VERSION ""

NS_ :

BS_:

BU_:

BO_ 256 CANERR_OVER_CURRENT: 8 Vector__XXX
 SG_ data_3 : 63|8@0+ (1,0) [0|0] "" Vector__XXX
 SG_ data_2 : 55|8@0+ (1,0) [0|0] "" Vector__XXX
 SG_ data_1 : 47|8@0+ (1,0) [0|0] "" Vector__XXX
 SG_ data_0 : 39|8@0+ (1,0) [0|0] "" Vector__XXX
 SG_ node_id : 7|32@0+ (1,0) [0|0] "" Vector__XXX

BO_ 257 CANERR_OVER_VOLTAGE: 8 Vector__XXX
 SG_ data_3 : 63|8@0+ (1,0) [0|0] "" Vector__XXX
 SG_ data_2 : 55|8@0+ (1,0) [0|0] "" Vector__XXX
 SG_ data_1 : 47|8@0+ (1,0) [0|0] "" Vector__XXX
 SG_ data_0 : 39|8@0+ (1,0) [0|0] "" Vector__XXX
 SG_ node_id : 7|32@0+ (1,0) [0|0] "" Vector__XXX

BO_ 258 CANNERR_OVER_VOLTAGE: 8 Vector__XXX
 SG_ data_3 : 63|8@0+ (1,0) [0|0] "" Vector__XXX
 SG_ data_2 : 55|8@0+ (1,0) [0|0] "" Vector__XXX
 SG_ data_1 : 47|8@0+ (1,0) [0|0] "" Vector__XXX
 SG_ data_0 : 39|8@0+ (1,0) [0|0] "" Vector__XXX
 SG_ node_id : 7|32@0+ (1,0) [0|0] "" Vector__XXX

BO_ 259 CANERR_GEN_ALARM: 8 Vector__XXX
 SG_ data_3 : 63|8@0+ (1,0) [0|0] "" Vector__XXX
 SG_ data_2 : 55|8@0+ (1,0) [0|0] "" Vector__XXX
 SG_ data_1 : 47|8@0+ (1,0) [0|0] "" Vector__XXX
 SG_ data_0 : 39|8@0+ (1,0) [0|0] "" Vector__XXX
 SG_ node_id : 7|32@0+ (1,0) [0|0] "" Vector__XXX

BO_ 260 CANERR_STORED_ERROR: 8 Vector__XXX
 SG_ data_3 : 63|8@0+ (1,0) [0|0] "" Vector__XXX
 SG_ data_2 : 55|8@0+ (1,0) [0|0] "" Vector__XXX
 SG_ data_1 : 47|8@0+ (1,0) [0|0] "" Vector__XXX
 SG_ data_0 : 39|8@0+ (1,0) [0|0] "" Vector__XXX
 SG_ node_id : 7|32@0+ (1,0) [0|0] "" Vector__XXX

BO_ 261 CANERR_RESERVED_105: 4 Vector__XXX
 SG_ node_id : 7|32@0+ (1,0) [0|0] "" Vector__XXX

BO_ 262 CANERR_RESERVED_106: 4 Vector__XXX
 SG_ node_id : 7|32@0+ (1,0) [0|0] "" Vector__XXX

BO_ 263 CANERR_RESERVED_107: 4 Vector__XXX
 SG_ node_id : 7|32@0+ (1,0) [0|0] "" Vector__XXX

BO_ 264 CANERR_RESERVED_108: 4 Vector__XXX
 SG_ node_id : 7|32@0+ (1,0) [0|0] "" Vector__XXX

BO_ 265 CANERR_RESERVED_109: 4 Vector__XXX
 SG_ node_id : 7|32@0+ (1,0) [0|0] "" Vector__XXX

BO_ 272 SW_RESERVED_110: 4 Vector__XXX
 SG_ node_id : 7|32@0+ (1,0) [0|0] "" Vector__XXX

BO_ 273 SW_RESERVED_111: 4 Vector__XXX
 SG_ node_id : 7|32@0+ (1,0) [0|0] "" Vector__XXX

BO_ 274 SW_SET_MODE: 6 Vector__XXX
 SG_ switch_mode : 47|8@0+ (1,0) [0|0] "" Vector__XXX
 SG_ switch_id : 39|8@0+ (1,0) [0|0] "" Vector__XXX
 SG_ node_id : 7|32@0+ (1,0) [0|0] "" Vector__XXX

BO_ 275 SW_SET_OFF: 5 Vector__XXX
 SG_ switch_id : 39|8@0+ (1,0) [0|0] "" Vector__XXX
 SG_ node_id : 7|32@0+ (1,0) [0|0] "" Vector__XXX

BO_ 276 SW_SET_ON: 5 Vector__XXX
 SG_ switch_id : 39|8@0+ (1,0) [0|0] "" Vector__XXX
 SG_ node_id : 7|32@0+ (1,0) [0|0] "" Vector__XXX

BO_ 277 SW_MOM_PRESS: 5 Vector__XXX
 SG_ switch_id : 39|8@0+ (1,0) [0|0] "" Vector__XXX
 SG_ node_id : 7|32@0+ (1,0) [0|0] "" Vector__XXX

BO_ 278 SW_SET_MOM_DUR: 6 Vector__XXX
 SG_ duration : 47|8@0+ (1,0) [0|0] "" Vector__XXX
 SG_ switch_id : 39|8@0+ (1,0) [0|0] "" Vector__XXX
 SG_ node_id : 7|32@0+ (1,0) [0|0] "" Vector__XXX

BO_ 279 SW_SET_PWM_DUTY: 6 Vector__XXX
 SG_ duty : 47|8@0+ (1,0) [0|0] "" Vector__XXX
 SG_ switch_id : 39|8@0+ (1,0) [0|0] "" Vector__XXX
 SG_ node_id : 7|32@0+ (1,0) [0|0] "" Vector__XXX

BO_ 280 SW_SET_PWM_FREQ: 6 Vector__XXX
 SG_ freq : 47|8@0+ (1,0) [0|0] "" Vector__XXX
 SG_ switch_id : 39|8@0+ (1,0) [0|0] "" Vector__XXX
 SG_ node_id : 7|32@0+ (1,0) [0|0] "" Vector__XXX

BO_ 281 SW_SET_BLINK_DELAY: 6 Vector__XXX
 SG_ blink_rate : 47|8@0+ (1,0) [0|0] "" Vector__XXX
 SG_ switch_id : 39|8@0+ (1,0) [0|0] "" Vector__XXX
 SG_ node_id : 7|32@0+ (1,0) [0|0] "" Vector__XXX

BO_ 282 SW_SET_STROBE_PAT: 6 Vector__XXX
 SG_ strobe_pattern : 47|8@0+ (1,0) [0|0] "" Vector__XXX
 SG_ switch_id : 39|8@0+ (1,0) [0|0] "" Vector__XXX
 SG_ node_id : 7|32@0+ (1,0) [0|0] "" Vector__XXX

BO_ 283 SW_SET_STATE_MEM: 6 Vector__XXX
 SG_ memory : 47|8@0+ (1,0) [0|0] "" Vector__XXX
 SG_ switch_id : 39|8@0+ (1,0) [0|0] "" Vector__XXX
 SG_ node_id : 7|32@0+ (1,0) [0|0] "" Vector__XXX

BO_ 284 SW_RESERVED_11C: 4 Vector__XXX
 SG_ node_id : 7|32@0+ (1,0) [0|0] "" Vector__XXX

BO_ 285 SW_RESERVED_11D: 4 Vector__XXX
 SG_ node_id : 7|32@0+ (1,0) [0|0] "" Vector__XXX

BO_ 286 SW_RESERVED_11E: 4 Vector__XXX
 SG_ node_id : 7|32@0+ (1,0) [0|0] "" Vector__XXX

BO_ 287 SW_RESERVED_11F: 4 Vector__XXX
 SG_ node_id : 7|32@0+ (1,0) [0|0] "" Vector__XXX

BO_ 314 SW_RESERVED_13A: 4 Vector__XXX
 SG_ node_id : 7|32@0+ (1,0) [0|0] "" Vector__XXX

BO_ 315 SW_RESERVED_13B: 4 Vector__XXX
 SG_ node_id : 7|32@0+ (1,0) [0|0] "" Vector__XXX

BO_ 316 SW_RESERVED_13C: 4 Vector__XXX
 SG_ node_id : 7|32@0+ (1,0) [0|0] "" Vector__XXX

BO_ 317 SW_RESERVED_13D: 4 Vector__XXX
 SG_ node_id : 7|32@0+ (1,0) [0|0] "" Vector__XXX

BO_ 318 SW_RESERVED_13E: 4 Vector__XXX
 SG_ node_id : 7|32@0+ (1,0) [0|0] "" Vector__XXX

BO_ 319 SW_RESERVED_13F: 4 Vector__XXX
 SG_ node_id : 7|32@0+ (1,0) [0|0] "" Vector__XXX

BO_ 512 SET_DISPLAY_OFF: 5 Vector__XXX
 SG_ display_id : 39|8@0+ (1,0) [0|0] "" Vector__XXX
 SG_ node_id : 7|32@0+ (1,0) [0|0] "" Vector__XXX

BO_ 513 SET_DISPLAY_ON: 5 Vector__XXX
 SG_ display_id : 39|8@0+ (1,0) [0|0] "" Vector__XXX
 SG_ node_id : 7|32@0+ (1,0) [0|0] "" Vector__XXX

BO_ 514 SET_DISPLAY_CLEAR: 5 Vector__XXX
 SG_ display_id : 39|8@0+ (1,0) [0|0] "" Vector__XXX
 SG_ node_id : 7|32@0+ (1,0) [0|0] "" Vector__XXX

BO_ 515 SET_DISPLAY_FLASH: 6 Vector__XXX
 SG_ flash_rate : 47|8@0+ (1,0) [0|0] "" Vector__XXX
 SG_ display_id : 39|8@0+ (1,0) [0|0] "" Vector__XXX
 SG_ node_id : 7|32@0+ (1,0) [0|0] "" Vector__XXX

BO_ 516 SET_DISPLAY_BACKLIGHT_COLOR: 6 Vector__XXX
 SG_ color_index : 47|8@0+ (1,0) [0|0] "" Vector__XXX
 SG_ display_id : 39|8@0+ (1,0) [0|0] "" Vector__XXX
 SG_ node_id : 7|32@0+ (1,0) [0|0] "" Vector__XXX

BO_ 517 SET_DISPLAY_BACKLIGHT_BRIGHTNESS: 6 Vector__XXX
 SG_ brightness : 47|8@0+ (1,0) [0|0] "" Vector__XXX
 SG_ display_id : 39|8@0+ (1,0) [0|0] "" Vector__XXX
 SG_ node_id : 7|32@0+ (1,0) [0|0] "" Vector__XXX

BO_ 518 REQ_DISPLAY_CONFIG: 7 Vector__XXX
 SG_ msg_id : 47|16@0+ (1,0) [0|0] "" Vector__XXX
 SG_ display_id : 39|8@0+ (1,0) [0|0] "" Vector__XXX
 SG_ node_id : 7|32@0+ (1,0) [0|0] "" Vector__XXX

BO_ 519 REQ_DISPLAY_DATA: 7 Vector__XXX
 SG_ msg_id : 47|16@0+ (1,0) [0|0] "" Vector__XXX
 SG_ display_id : 39|8@0+ (1,0) [0|0] "" Vector__XXX
 SG_ node_id : 7|32@0+ (1,0) [0|0] "" Vector__XXX

BO_ 520 SET_OLED_FIELD_COLOR: 6 Vector__XXX
 SG_ color_index : 47|8@0+ (1,0) [0|0] "" Vector__XXX
 SG_ display_id : 39|8@0+ (1,0) [0|0] "" Vector__XXX
 SG_ node_id : 7|32@0+ (1,0) [0|0] "" Vector__XXX

BO_ 521 SET_OLED_FIELD_BLINK: 7 Vector__XXX
 SG_ blink_rate : 47|16@0+ (1,0) [0|0] "" Vector__XXX
 SG_ display_id : 39|8@0+ (1,0) [0|0] "" Vector__XXX
 SG_ node_id : 7|32@0+ (1,0) [0|0] "" Vector__XXX

BO_ 522 SET_OLED_FIELD_STROBE: 6 Vector__XXX
 SG_ strobe_pattern : 47|8@0+ (1,0) [0|0] "" Vector__XXX
 SG_ display_id : 39|8@0+ (1,0) [0|0] "" Vector__XXX
 SG_ node_id : 7|32@0+ (1,0) [0|0] "" Vector__XXX

BO_ 523 SET_DISPLAY_RESERVED_20B: 4 Vector__XXX
 SG_ node_id : 7|32@0+ (1,0) [0|0] "" Vector__XXX

BO_ 524 SET_DISPLAY_RESERVED_20C: 4 Vector__XXX
 SG_ node_id : 7|32@0+ (1,0) [0|0] "" Vector__XXX

BO_ 525 DISPLAY_DATA_MSG: 8 Vector__XXX
 SG_ display_data : 7|64@0+ (1,0) [0|0] "" Vector__XXX

BO_ 526 DISPLAY_DATA_ACK: 8 Vector__XXX
 SG_ display_data : 7|64@0+ (1,0) [0|0] "" Vector__XXX

BO_ 527 SET_DISPLAY_RESERVED_20F: 4 Vector__XXX
 SG_ node_id : 7|32@0+ (1,0) [0|0] "" Vector__XXX

BO_ 528 SET_ARGB_STRIP_COLOR: 6 Vector__XXX
 SG_ color_index : 47|8@0+ (1,0) [0|0] "" Vector__XXX
 SG_ display_id : 39|8@0+ (1,0) [0|0] "" Vector__XXX
 SG_ node_id : 7|32@0+ (1,0) [0|0] "" Vector__XXX

BO_ 529 SET_ARGBW_STRIP_COLOR: 6 Vector__XXX
 SG_ color_index : 47|8@0+ (1,0) [0|0] "" Vector__XXX
 SG_ display_id : 39|8@0+ (1,0) [0|0] "" Vector__XXX
 SG_ node_id : 7|32@0+ (1,0) [0|0] "" Vector__XXX

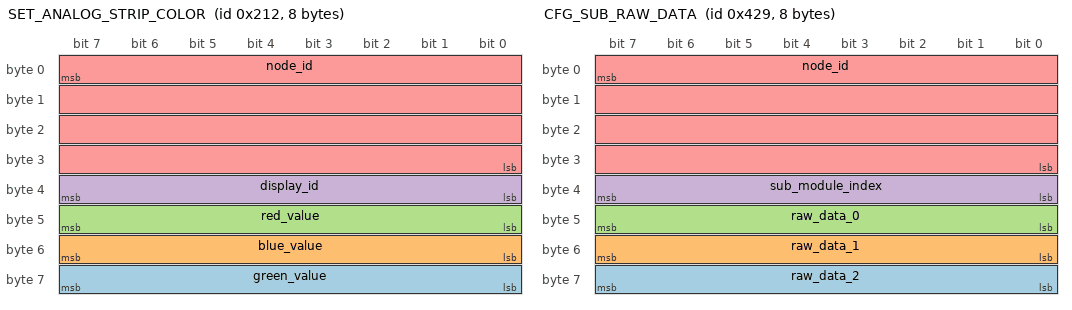
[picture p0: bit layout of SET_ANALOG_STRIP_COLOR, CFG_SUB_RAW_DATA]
BO_ 530 SET_ANALOG_STRIP_COLOR: 8 Vector__XXX
 SG_ green_value : 63|8@0+ (1,0) [0|0] "" Vector__XXX
 SG_ blue_value : 55|8@0+ (1,0) [0|0] "" Vector__XXX
 SG_ red_value : 47|8@0+ (1,0) [0|0] "" Vector__XXX
 SG_ display_id : 39|8@0+ (1,0) [0|0] "" Vector__XXX
 SG_ node_id : 7|32@0+ (1,0) [0|0] "" Vector__XXX

BO_ 531 SET_ADDR_STRIP_EFFECT: 6 Vector__XXX
 SG_ effect_index : 47|8@0+ (1,0) [0|0] "" Vector__XXX
 SG_ display_id : 39|8@0+ (1,0) [0|0] "" Vector__XXX
 SG_ node_id : 7|32@0+ (1,0) [0|0] "" Vector__XXX

BO_ 532 SET_LED_STRIP_BRIGHTNESS: 6 Vector__XXX
 SG_ brightness : 47|8@0+ (1,0) [0|0] "" Vector__XXX
 SG_ display_id : 39|8@0+ (1,0) [0|0] "" Vector__XXX
 SG_ node_id : 7|32@0+ (1,0) [0|0] "" Vector__XXX

BO_ 533 SET_LED_STRIP_OFF: 5 Vector__XXX
 SG_ display_id : 39|8@0+ (1,0) [0|0] "" Vector__XXX
 SG_ node_id : 7|32@0+ (1,0) [0|0] "" Vector__XXX

BO_ 534 SET_LED_STRIP_ON: 5 Vector__XXX
 SG_ display_id : 39|8@0+ (1,0) [0|0] "" Vector__XXX
 SG_ node_id : 7|32@0+ (1,0) [0|0] "" Vector__XXX

BO_ 535 SET_LED_RESERVED_217: 4 Vector__XXX
 SG_ node_id : 7|32@0+ (1,0) [0|0] "" Vector__XXX

BO_ 536 SET_LED_RESERVED_218: 4 Vector__XXX
 SG_ node_id : 7|32@0+ (1,0) [0|0] "" Vector__XXX

BO_ 537 SET_LED_RESERVED_219: 4 Vector__XXX
 SG_ node_id : 7|32@0+ (1,0) [0|0] "" Vector__XXX

BO_ 538 SET_LED_RESERVED_21A: 4 Vector__XXX
 SG_ node_id : 7|32@0+ (1,0) [0|0] "" Vector__XXX

BO_ 539 SET_LED_RESERVED_21B: 4 Vector__XXX
 SG_ node_id : 7|32@0+ (1,0) [0|0] "" Vector__XXX

BO_ 540 SET_LED_RESERVED_21C: 4 Vector__XXX
 SG_ node_id : 7|32@0+ (1,0) [0|0] "" Vector__XXX

BO_ 541 SET_LED_RESERVED_21D: 4 Vector__XXX
 SG_ node_id : 7|32@0+ (1,0) [0|0] "" Vector__XXX

BO_ 542 SET_LED_RESERVED_21E: 4 Vector__XXX
 SG_ node_id : 7|32@0+ (1,0) [0|0] "" Vector__XXX

BO_ 543 SET_LED_RESERVED_21F: 4 Vector__XXX
 SG_ node_id : 7|32@0+ (1,0) [0|0] "" Vector__XXX

BO_ 544 SET_ARGB_BUTTON_COLOR: 6 Vector__XXX
 SG_ color_index : 47|8@0+ (1,0) [0|0] "" Vector__XXX
 SG_ button_id : 39|8@0+ (1,0) [0|0] "" Vector__XXX
 SG_ node_id : 7|32@0+ (1,0) [0|0] "" Vector__XXX

BO_ 545 SET_ARGB_BUTTON_LED_MODE: 6 Vector__XXX
 SG_ mode_select : 47|8@0+ (1,0) [0|0] "" Vector__XXX
 SG_ button_id : 39|8@0+ (1,0) [0|0] "" Vector__XXX
 SG_ node_id : 7|32@0+ (1,0) [0|0] "" Vector__XXX

BO_ 546 SET_BUTTON_MODE: 4 Vector__XXX
 SG_ node_id : 7|32@0+ (1,0) [0|0] "" Vector__XXX

BO_ 547 SET_BUTTON_RESERVED_223: 4 Vector__XXX
 SG_ node_id : 7|32@0+ (1,0) [0|0] "" Vector__XXX

BO_ 548 SET_BUTTON_RESERVED_224: 4 Vector__XXX
 SG_ node_id : 7|32@0+ (1,0) [0|0] "" Vector__XXX

BO_ 549 SET_BUTTON_RESERVED_225: 4 Vector__XXX
 SG_ node_id : 7|32@0+ (1,0) [0|0] "" Vector__XXX

BO_ 550 SET_BUTTON_RESERVED_226: 4 Vector__XXX
 SG_ node_id : 7|32@0+ (1,0) [0|0] "" Vector__XXX

BO_ 551 SET_BUTTON_RESERVED_227: 4 Vector__XXX
 SG_ node_id : 7|32@0+ (1,0) [0|0] "" Vector__XXX

BO_ 552 SET_BUTTON_RESERVED_228: 4 Vector__XXX
 SG_ node_id : 7|32@0+ (1,0) [0|0] "" Vector__XXX

BO_ 553 SET_BUTTON_RESERVED_229: 4 Vector__XXX
 SG_ node_id : 7|32@0+ (1,0) [0|0] "" Vector__XXX

BO_ 554 SET_BUTTON_RESERVED_22A: 4 Vector__XXX
 SG_ node_id : 7|32@0+ (1,0) [0|0] "" Vector__XXX

BO_ 555 SET_BUTTON_RESERVED_22B: 4 Vector__XXX
 SG_ node_id : 7|32@0+ (1,0) [0|0] "" Vector__XXX

BO_ 556 SET_BUTTON_RESERVED_22C: 4 Vector__XXX
 SG_ node_id : 7|32@0+ (1,0) [0|0] "" Vector__XXX

BO_ 557 SET_BUTTON_RESERVED_22D: 4 Vector__XXX
 SG_ node_id : 7|32@0+ (1,0) [0|0] "" Vector__XXX

BO_ 558 SET_BUTTON_RESERVED_22E: 4 Vector__XXX
 SG_ node_id : 7|32@0+ (1,0) [0|0] "" Vector__XXX

BO_ 559 SET_BUTTON_RESERVED_22F: 4 Vector__XXX
 SG_ node_id : 7|32@0+ (1,0) [0|0] "" Vector__XXX

BO_ 1024 ACK_INTRO: 4 Vector__XXX
 SG_ node_id : 7|32@0+ (1,0) [0|0] "" Vector__XXX

BO_ 1025 REQ_NODE_INTRO: 4 Vector__XXX
 SG_ node_id : 7|32@0+ (1,0) [0|0] "" Vector__XXX

BO_ 1026 MSG_NORM_OPER: 4 Vector__XXX
 SG_ node_id : 7|32@0+ (1,0) [0|0] "" Vector__XXX

BO_ 1027 MSG_HALT_OPER: 4 Vector__XXX
 SG_ node_id : 7|32@0+ (1,0) [0|0] "" Vector__XXX

BO_ 1028 REQ_NODECHECK: 4 Vector__XXX
 SG_ node_id : 7|32@0+ (1,0) [0|0] "" Vector__XXX

BO_ 1029 REQ_HEALTHCHECK: 4 Vector__XXX
 SG_ node_id : 7|32@0+ (1,0) [0|0] "" Vector__XXX

BO_ 1030 REQ_IFACE: 4 Vector__XXX
 SG_ node_id : 7|32@0+ (1,0) [0|0] "" Vector__XXX

BO_ 1031 REQ_SWITCHBOX: 4 Vector__XXX
 SG_ node_id : 7|32@0+ (1,0) [0|0] "" Vector__XXX

BO_ 1032 REQ_RESERVED_408: 4 Vector__XXX
 SG_ node_id : 7|32@0+ (1,0) [0|0] "" Vector__XXX

BO_ 1033 REQ_RESERVED_409: 4 Vector__XXX
 SG_ node_id : 7|32@0+ (1,0) [0|0] "" Vector__XXX

BO_ 1034 REQ_RESERVED_40A: 4 Vector__XXX
 SG_ node_id : 7|32@0+ (1,0) [0|0] "" Vector__XXX

BO_ 1035 REQ_RESERVED_40B: 4 Vector__XXX
 SG_ node_id : 7|32@0+ (1,0) [0|0] "" Vector__XXX

BO_ 1036 DATA_EPOCH: 8 Vector__XXX
 SG_ unixtime : 39|32@0+ (1,0) [0|0] "" Vector__XXX
 SG_ node_id : 7|32@0+ (1,0) [0|0] "" Vector__XXX

BO_ 1037 DATA_SENSOR_MSG: 6 Vector__XXX
 SG_ data_msg_id : 39|16@0+ (1,0) [0|0] "" Vector__XXX
 SG_ node_id : 7|32@0+ (1,0) [0|0] "" Vector__XXX

BO_ 1038 REQ_RESERVED_40E: 4 Vector__XXX
 SG_ node_id : 7|32@0+ (1,0) [0|0] "" Vector__XXX

BO_ 1039 REQ_RESERVED_40F: 4 Vector__XXX
 SG_ node_id : 7|32@0+ (1,0) [0|0] "" Vector__XXX

BO_ 1040 REQ_DIGITAL_INPUTS: 4 Vector__XXX
 SG_ node_id : 7|32@0+ (1,0) [0|0] "" Vector__XXX

BO_ 1041 REQ_DIGITAL_OUTPUTS: 4 Vector__XXX
 SG_ node_id : 7|32@0+ (1,0) [0|0] "" Vector__XXX

BO_ 1042 REQ_DISPLAYS: 4 Vector__XXX
 SG_ node_id : 7|32@0+ (1,0) [0|0] "" Vector__XXX

BO_ 1043 REQ_TEMP_SENSOR: 4 Vector__XXX
 SG_ node_id : 7|32@0+ (1,0) [0|0] "" Vector__XXX

BO_ 1044 REQ_VOLT_SENSOR: 4 Vector__XXX
 SG_ node_id : 7|32@0+ (1,0) [0|0] "" Vector__XXX

BO_ 1045 REQ_AMP_SENSOR: 4 Vector__XXX
 SG_ node_id : 7|32@0+ (1,0) [0|0] "" Vector__XXX

BO_ 1046 REQ_ANALOG_INPUTS: 4 Vector__XXX
 SG_ node_id : 7|32@0+ (1,0) [0|0] "" Vector__XXX

BO_ 1047 REQ_AMBIENT_LIGHT: 4 Vector__XXX
 SG_ node_id : 7|32@0+ (1,0) [0|0] "" Vector__XXX

BO_ 1048 REQ_IMU_SENSORS: 4 Vector__XXX
 SG_ node_id : 7|32@0+ (1,0) [0|0] "" Vector__XXX

BO_ 1049 REQ_RESERVED_419: 4 Vector__XXX
 SG_ node_id : 7|32@0+ (1,0) [0|0] "" Vector__XXX

BO_ 1050 REQ_RESERVED_41A: 4 Vector__XXX
 SG_ node_id : 7|32@0+ (1,0) [0|0] "" Vector__XXX

BO_ 1051 REQ_RESERVED_41B: 4 Vector__XXX
 SG_ node_id : 7|32@0+ (1,0) [0|0] "" Vector__XXX

BO_ 1052 REQ_RESERVED_41C: 4 Vector__XXX
 SG_ node_id : 7|32@0+ (1,0) [0|0] "" Vector__XXX

BO_ 1053 REQ_RESERVED_41D: 4 Vector__XXX
 SG_ node_id : 7|32@0+ (1,0) [0|0] "" Vector__XXX

BO_ 1054 REQ_RESERVED_41E: 4 Vector__XXX
 SG_ node_id : 7|32@0+ (1,0) [0|0] "" Vector__XXX

BO_ 1055 REQ_RESERVED_41F: 4 Vector__XXX
 SG_ node_id : 7|32@0+ (1,0) [0|0] "" Vector__XXX

BO_ 1056 CFG_RESERVED_420: 4 Vector__XXX
 SG_ node_id : 7|32@0+ (1,0) [0|0] "" Vector__XXX

BO_ 1057 CFG_RESERVED_421: 4 Vector__XXX
 SG_ node_id : 7|32@0+ (1,0) [0|0] "" Vector__XXX

BO_ 1058 CFG_RESERVED_422: 4 Vector__XXX
 SG_ node_id : 7|32@0+ (1,0) [0|0] "" Vector__XXX

BO_ 1059 CFG_RESERVED_423: 4 Vector__XXX
 SG_ node_id : 7|32@0+ (1,0) [0|0] "" Vector__XXX

BO_ 1060 CFG_RESERVED_424: 4 Vector__XXX
 SG_ node_id : 7|32@0+ (1,0) [0|0] "" Vector__XXX

BO_ 1061 CFG_RESERVED_425: 4 Vector__XXX
 SG_ node_id : 7|32@0+ (1,0) [0|0] "" Vector__XXX

BO_ 1062 CFG_RESERVED_426: 4 Vector__XXX
 SG_ node_id : 7|32@0+ (1,0) [0|0] "" Vector__XXX

BO_ 1063 CFG_RESERVED_427: 4 Vector__XXX
 SG_ node_id : 7|32@0+ (1,0) [0|0] "" Vector__XXX

BO_ 1064 CFG_RESERVED_428: 4 Vector__XXX
 SG_ node_id : 7|32@0+ (1,0) [0|0] "" Vector__XXX

BO_ 1065 CFG_SUB_RAW_DATA: 8 Vector__XXX
 SG_ raw_data_2 : 63|8@0+ (1,0) [0|0] "" Vector__XXX
 SG_ raw_data_1 : 55|8@0+ (1,0) [0|0] "" Vector__XXX
 SG_ raw_data_0 : 47|8@0+ (1,0) [0|0] "" Vector__XXX
 SG_ sub_module_index : 39|8@0+ (1,0) [0|0] "" Vector__XXX
 SG_ node_id : 7|32@0+ (1,0) [0|0] "" Vector__XXX

BO_ 1066 CFG_NODE_DATA_MSG: 7 Vector__XXX
 SG_ datamsg_dlc : 55|8@0+ (1,0) [0|0] "" Vector__XXX
 SG_ datamsg_id : 39|16@0+ (1,0) [0|0] "" Vector__XXX
 SG_ node_id : 7|32@0+ (1,0) [0|0] "" Vector__XXX

BO_ 1067 CFG_NODE_INTRO_MSG: 7 Vector__XXX
 SG_ intromsg_dlc : 55|8@0+ (1,0) [0|0] "" Vector__XXX
 SG_ intromsg_id : 39|16@0+ (1,0) [0|0] "" Vector__XXX
 SG_ node_id : 7|32@0+ (1,0) [0|0] "" Vector__XXX

BO_ 1068 CFG_SUB_DATA_MSG: 8 Vector__XXX
 SG_ datamsg_dlc : 63|8@0+ (1,0) [0|0] "" Vector__XXX
 SG_ datamsg_id : 47|16@0+ (1,0) [0|0] "" Vector__XXX
 SG_ sub_module_index : 39|8@0+ (1,0) [0|0] "" Vector__XXX
 SG_ node_id : 7|32@0+ (1,0) [0|0] "" Vector__XXX

BO_ 1069 CFG_SUB_INTRO_MSG: 8 Vector__XXX
 SG_ intromsg_dlc : 63|8@0+ (1,0) [0|0] "" Vector__XXX
 SG_ intromsg_id : 47|16@0+ (1,0) [0|0] "" Vector__XXX
 SG_ sub_module_index : 39|8@0+ (1,0) [0|0] "" Vector__XXX
 SG_ node_id : 7|32@0+ (1,0) [0|0] "" Vector__XXX

BO_ 1070 COLORPICKER_READ_NVS: 4 Vector__XXX
 SG_ node_id : 7|32@0+ (1,0) [0|0] "" Vector__XXX

BO_ 1071 COLORPICKER_WRITE_NVS: 4 Vector__XXX
 SG_ node_id : 7|32@0+ (1,0) [0|0] "" Vector__XXX

BO_ 1072 COLORPICKER_SEND_LIST: 4 Vector__XXX
 SG_ node_id : 7|32@0+ (1,0) [0|0] "" Vector__XXX

BO_ 1073 COLORPICKER_PURGE_LIST: 4 Vector__XXX
 SG_ node_id : 7|32@0+ (1,0) [0|0] "" Vector__XXX

BO_ 1074 COLORPICKER_DEL_NODE: 8 Vector__XXX
 SG_ remote_id : 39|32@0+ (1,0) [0|0] "" Vector__XXX
 SG_ node_id : 7|32@0+ (1,0) [0|0] "" Vector__XXX

BO_ 1075 COLORPICKER_ADD_NODE: 8 Vector__XXX
 SG_ remote_id : 39|32@0+ (1,0) [0|0] "" Vector__XXX
 SG_ node_id : 7|32@0+ (1,0) [0|0] "" Vector__XXX

BO_ 1076 CFG_ERASE_NVS: 4 Vector__XXX
 SG_ node_id : 7|32@0+ (1,0) [0|0] "" Vector__XXX

BO_ 1077 CFG_REBOOT: 4 Vector__XXX
 SG_ node_id : 7|32@0+ (1,0) [0|0] "" Vector__XXX

BO_ 1078 CFG_WRITE_NVS: 6 Vector__XXX
 SG_ crc_16 : 39|16@0+ (1,0) [0|0] "" Vector__XXX
 SG_ node_id : 7|32@0+ (1,0) [0|0] "" Vector__XXX

BO_ 1079 CFG_READ_NVS: 6 Vector__XXX
 SG_ crc_16 : 39|16@0+ (1,0) [0|0] "" Vector__XXX
 SG_ node_id : 7|32@0+ (1,0) [0|0] "" Vector__XXX

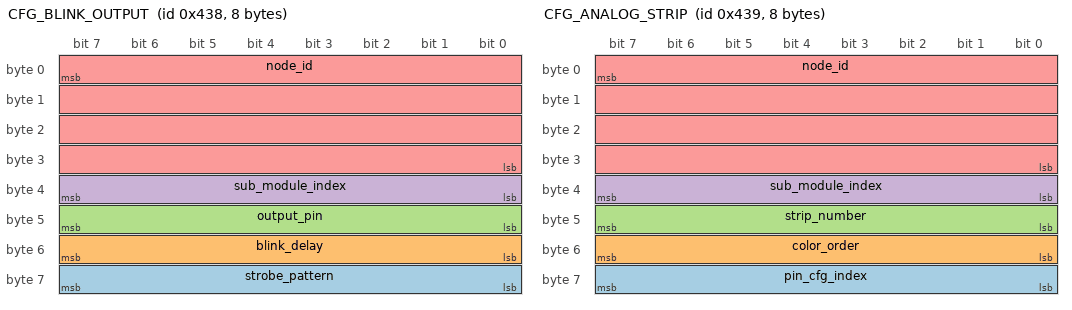
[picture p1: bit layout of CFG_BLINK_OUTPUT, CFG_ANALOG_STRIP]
BO_ 1080 CFG_BLINK_OUTPUT: 8 Vector__XXX
 SG_ strobe_pattern : 63|8@0+ (1,0) [0|0] "" Vector__XXX
 SG_ blink_delay : 55|8@0+ (1,0) [0|0] "" Vector__XXX
 SG_ output_pin : 47|8@0+ (1,0) [0|0] "" Vector__XXX
 SG_ sub_module_index : 39|8@0+ (1,0) [0|0] "" Vector__XXX
 SG_ node_id : 7|32@0+ (1,0) [0|0] "" Vector__XXX

BO_ 1081 CFG_ANALOG_STRIP: 8 Vector__XXX
 SG_ pin_cfg_index : 63|8@0+ (1,0) [0|0] "" Vector__XXX
 SG_ color_order : 55|8@0+ (1,0) [0|0] "" Vector__XXX
 SG_ strip_number : 47|8@0+ (1,0) [0|0] "" Vector__XXX
 SG_ sub_module_index : 39|8@0+ (1,0) [0|0] "" Vector__XXX
 SG_ node_id : 7|32@0+ (1,0) [0|0] "" Vector__XXX

BO_ 1082 CFG_ARGB_STRIP: 8 Vector__XXX
 SG_ led_count : 55|16@0+ (1,0) [0|0] "" Vector__XXX
 SG_ output_pin : 47|8@0+ (1,0) [0|0] "" Vector__XXX
 SG_ sub_module_index : 39|8@0+ (1,0) [0|0] "" Vector__XXX
 SG_ node_id : 7|32@0+ (1,0) [0|0] "" Vector__XXX

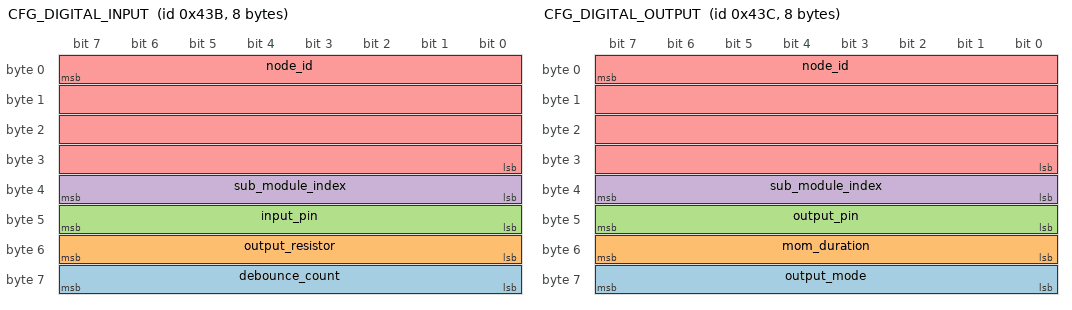
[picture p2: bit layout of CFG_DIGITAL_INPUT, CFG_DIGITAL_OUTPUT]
BO_ 1083 CFG_DIGITAL_INPUT: 8 Vector__XXX
 SG_ debounce_count : 63|8@0+ (1,0) [0|0] "" Vector__XXX
 SG_ output_resistor : 55|8@0+ (1,0) [0|0] "" Vector__XXX
 SG_ input_pin : 47|8@0+ (1,0) [0|0] "" Vector__XXX
 SG_ sub_module_index : 39|8@0+ (1,0) [0|0] "" Vector__XXX
 SG_ node_id : 7|32@0+ (1,0) [0|0] "" Vector__XXX

BO_ 1084 CFG_DIGITAL_OUTPUT: 8 Vector__XXX
 SG_ output_mode : 63|8@0+ (1,0) [0|0] "" Vector__XXX
 SG_ mom_duration : 55|8@0+ (1,0) [0|0] "" Vector__XXX
 SG_ output_pin : 47|8@0+ (1,0) [0|0] "" Vector__XXX
 SG_ sub_module_index : 39|8@0+ (1,0) [0|0] "" Vector__XXX
 SG_ node_id : 7|32@0+ (1,0) [0|0] "" Vector__XXX

BO_ 1085 CFG_ANALOG_INPUT: 8 Vector__XXX
 SG_ over_sample_cnt : 55|16@0+ (1,0) [0|0] "" Vector__XXX
 SG_ input_pin : 47|8@0+ (1,0) [0|0] "" Vector__XXX
 SG_ sub_module_index : 39|8@0+ (1,0) [0|0] "" Vector__XXX
 SG_ node_id : 7|32@0+ (1,0) [0|0] "" Vector__XXX

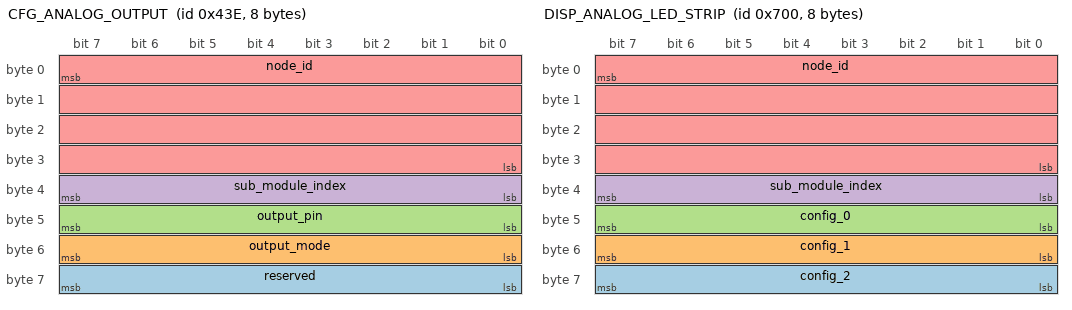
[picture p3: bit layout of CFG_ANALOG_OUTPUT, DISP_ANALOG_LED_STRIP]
BO_ 1086 CFG_ANALOG_OUTPUT: 8 Vector__XXX
 SG_ reserved : 63|8@0+ (1,0) [0|0] "" Vector__XXX
 SG_ output_mode : 55|8@0+ (1,0) [0|0] "" Vector__XXX
 SG_ output_pin : 47|8@0+ (1,0) [0|0] "" Vector__XXX
 SG_ sub_module_index : 39|8@0+ (1,0) [0|0] "" Vector__XXX
 SG_ node_id : 7|32@0+ (1,0) [0|0] "" Vector__XXX

BO_ 1087 CFG_PWM_OUTPUT: 8 Vector__XXX
 SG_ pwm_freq : 55|16@0+ (1,0) [0|0] "" Vector__XXX
 SG_ output_pin : 47|8@0+ (1,0) [0|0] "" Vector__XXX
 SG_ sub_module_index : 39|8@0+ (1,0) [0|0] "" Vector__XXX
 SG_ node_id : 7|32@0+ (1,0) [0|0] "" Vector__XXX

BO_ 1280 DATA_BUTTON_DOWN: 7 Vector__XXX
 SG_ event_data : 47|16@0+ (1,0) [0|0] "" Vector__XXX
 SG_ button_id : 39|8@0+ (1,0) [0|0] "" Vector__XXX
 SG_ node_id : 7|32@0+ (1,0) [0|0] "" Vector__XXX

BO_ 1281 DATA_BUTTON_UP: 7 Vector__XXX
 SG_ event_data : 47|16@0+ (1,0) [0|0] "" Vector__XXX
 SG_ button_id : 39|8@0+ (1,0) [0|0] "" Vector__XXX
 SG_ node_id : 7|32@0+ (1,0) [0|0] "" Vector__XXX

BO_ 1282 DATA_KEYSWITCH_LOCK: 7 Vector__XXX
 SG_ event_data : 47|16@0+ (1,0) [0|0] "" Vector__XXX
 SG_ button_id : 39|8@0+ (1,0) [0|0] "" Vector__XXX
 SG_ node_id : 7|32@0+ (1,0) [0|0] "" Vector__XXX

BO_ 1283 DATA_KEYSWITCH_UNLOCK: 7 Vector__XXX
 SG_ event_data : 47|16@0+ (1,0) [0|0] "" Vector__XXX
 SG_ button_id : 39|8@0+ (1,0) [0|0] "" Vector__XXX
 SG_ node_id : 7|32@0+ (1,0) [0|0] "" Vector__XXX

BO_ 1284 DATA_DIAL_CLOCKWISE: 7 Vector__XXX
 SG_ event_data : 47|16@0+ (1,0) [0|0] "" Vector__XXX
 SG_ button_id : 39|8@0+ (1,0) [0|0] "" Vector__XXX
 SG_ node_id : 7|32@0+ (1,0) [0|0] "" Vector__XXX

BO_ 1285 DATA_DIAL_COUNTER_CLOCKWISE: 7 Vector__XXX
 SG_ event_data : 47|16@0+ (1,0) [0|0] "" Vector__XXX
 SG_ button_id : 39|8@0+ (1,0) [0|0] "" Vector__XXX
 SG_ node_id : 7|32@0+ (1,0) [0|0] "" Vector__XXX

BO_ 1286 DATA_DIAL_CLICK: 7 Vector__XXX
 SG_ event_data : 47|16@0+ (1,0) [0|0] "" Vector__XXX
 SG_ button_id : 39|8@0+ (1,0) [0|0] "" Vector__XXX
 SG_ node_id : 7|32@0+ (1,0) [0|0] "" Vector__XXX

BO_ 1287 DATA_EXTERNAL_CURRENT: 8 Vector__XXX
 SG_ sensor_data : 47|24@0+ (1,0) [0|0] "" Vector__XXX
 SG_ sensor_id : 39|8@0+ (1,0) [0|0] "" Vector__XXX
 SG_ node_id : 7|32@0+ (1,0) [0|0] "" Vector__XXX

BO_ 1288 DATA_CONTACT_CLOSED: 7 Vector__XXX
 SG_ event_data : 47|16@0+ (1,0) [0|0] "" Vector__XXX
 SG_ button_id : 39|8@0+ (1,0) [0|0] "" Vector__XXX
 SG_ node_id : 7|32@0+ (1,0) [0|0] "" Vector__XXX

BO_ 1289 DATA_CONTACT_OPENED: 7 Vector__XXX
 SG_ event_data : 47|16@0+ (1,0) [0|0] "" Vector__XXX
 SG_ button_id : 39|8@0+ (1,0) [0|0] "" Vector__XXX
 SG_ node_id : 7|32@0+ (1,0) [0|0] "" Vector__XXX

BO_ 1290 DATA_INTERNAL_PCB_TEMP: 8 Vector__XXX
 SG_ sensor_data : 47|24@0+ (1,0) [0|0] "" Vector__XXX
 SG_ sensor_id : 39|8@0+ (1,0) [0|0] "" Vector__XXX
 SG_ node_id : 7|32@0+ (1,0) [0|0] "" Vector__XXX

BO_ 1291 DATA_INTERNAL_PCB_VOLTS: 8 Vector__XXX
 SG_ sensor_data : 47|24@0+ (1,0) [0|0] "" Vector__XXX
 SG_ sensor_id : 39|8@0+ (1,0) [0|0] "" Vector__XXX
 SG_ node_id : 7|32@0+ (1,0) [0|0] "" Vector__XXX

BO_ 1292 DATA_INTERNAL_PCB_CURRENT: 8 Vector__XXX
 SG_ sensor_data : 47|24@0+ (1,0) [0|0] "" Vector__XXX
 SG_ sensor_id : 39|8@0+ (1,0) [0|0] "" Vector__XXX
 SG_ node_id : 7|32@0+ (1,0) [0|0] "" Vector__XXX

BO_ 1293 DATA_EXTERNAL_TEMPERATURE: 8 Vector__XXX
 SG_ sensor_data : 47|24@0+ (1,0) [0|0] "" Vector__XXX
 SG_ sensor_id : 39|8@0+ (1,0) [0|0] "" Vector__XXX
 SG_ node_id : 7|32@0+ (1,0) [0|0] "" Vector__XXX

BO_ 1294 DATA_EXTERNAL_VOLTS: 8 Vector__XXX
 SG_ sensor_data : 47|24@0+ (1,0) [0|0] "" Vector__XXX
 SG_ sensor_id : 39|8@0+ (1,0) [0|0] "" Vector__XXX
 SG_ node_id : 7|32@0+ (1,0) [0|0] "" Vector__XXX

BO_ 1295 DATA_ADC_RAW: 7 Vector__XXX
 SG_ sensor_data : 47|16@0+ (1,0) [0|0] "" Vector__XXX
 SG_ sensor_id : 39|8@0+ (1,0) [0|0] "" Vector__XXX
 SG_ node_id : 7|32@0+ (1,0) [0|0] "" Vector__XXX

BO_ 1296 DATA_AMBIENT_LIGHT_USE_PRIV_MSG: 5 Vector__XXX
 SG_ sensor_id : 39|8@0+ (1,0) [0|0] "" Vector__XXX
 SG_ node_id : 7|32@0+ (1,0) [0|0] "" Vector__XXX

BO_ 1297 DATA_IMU_X_AXIS: 5 Vector__XXX
 SG_ sensor_id : 39|8@0+ (1,0) [0|0] "" Vector__XXX
 SG_ node_id : 7|32@0+ (1,0) [0|0] "" Vector__XXX

BO_ 1298 DATA_IMU_Y_AXIS: 5 Vector__XXX
 SG_ sensor_id : 39|8@0+ (1,0) [0|0] "" Vector__XXX
 SG_ node_id : 7|32@0+ (1,0) [0|0] "" Vector__XXX

BO_ 1299 DATA_IMU_Z_AXIS: 5 Vector__XXX
 SG_ sensor_id : 39|8@0+ (1,0) [0|0] "" Vector__XXX
 SG_ node_id : 7|32@0+ (1,0) [0|0] "" Vector__XXX

BO_ 1300 DATA_IMU_X_GYRO: 5 Vector__XXX
 SG_ sensor_id : 39|8@0+ (1,0) [0|0] "" Vector__XXX
 SG_ node_id : 7|32@0+ (1,0) [0|0] "" Vector__XXX

BO_ 1301 DATA_IMU_Y_GYRO: 5 Vector__XXX
 SG_ sensor_id : 39|8@0+ (1,0) [0|0] "" Vector__XXX
 SG_ node_id : 7|32@0+ (1,0) [0|0] "" Vector__XXX

BO_ 1302 DATA_IMU_Z_GYRO: 5 Vector__XXX
 SG_ sensor_id : 39|8@0+ (1,0) [0|0] "" Vector__XXX
 SG_ node_id : 7|32@0+ (1,0) [0|0] "" Vector__XXX

BO_ 1303 DATA_IMU_TEMPERATURE: 8 Vector__XXX
 SG_ sensor_data : 39|32@0+ (1,0) [0|0] "" Vector__XXX
 SG_ node_id : 7|32@0+ (1,0) [0|0] "" Vector__XXX

BO_ 1304 DATA_ANALOG_KNOB_MV: 8 Vector__XXX
 SG_ sensor_data : 47|24@0+ (1,0) [0|0] "" Vector__XXX
 SG_ sensor_id : 39|8@0+ (1,0) [0|0] "" Vector__XXX
 SG_ node_id : 7|32@0+ (1,0) [0|0] "" Vector__XXX

BO_ 1305 DATA_DATA_RESERVED_519: 4 Vector__XXX
 SG_ node_id : 7|32@0+ (1,0) [0|0] "" Vector__XXX

BO_ 1306 DATA_NODE_CPU_TEMP: 8 Vector__XXX
 SG_ sensor_data : 39|32@0+ (1,0) [0|0] "" Vector__XXX
 SG_ node_id : 7|32@0+ (1,0) [0|0] "" Vector__XXX

BO_ 1307 DATA_NODE_BOOT_TIMESTAMP: 8 Vector__XXX
 SG_ unixtime : 39|32@0+ (1,0) [0|0] "" Vector__XXX
 SG_ node_id : 7|32@0+ (1,0) [0|0] "" Vector__XXX

BO_ 1308 DATA_TOUCHSCREEN_EVENT: 4 Vector__XXX
 SG_ node_id : 7|32@0+ (1,0) [0|0] "" Vector__XXX

BO_ 1309 COLORPICKER_LIST_MEMBER: 4 Vector__XXX
 SG_ node_id : 7|32@0+ (1,0) [0|0] "" Vector__XXX

BO_ 1310 COLORPICKER_END_OF_LIST: 4 Vector__XXX
 SG_ node_id : 7|32@0+ (1,0) [0|0] "" Vector__XXX

BO_ 1311 DATA_RESERVED_51F: 4 Vector__XXX
 SG_ node_id : 7|32@0+ (1,0) [0|0] "" Vector__XXX

BO_ 1312 DATA_DISPLAY_OFF: 5 Vector__XXX
 SG_ display_id : 39|8@0+ (1,0) [0|0] "" Vector__XXX
 SG_ node_id : 7|32@0+ (1,0) [0|0] "" Vector__XXX

BO_ 1313 DATA_DISPLAY_ON: 5 Vector__XXX
 SG_ display_id : 39|8@0+ (1,0) [0|0] "" Vector__XXX
 SG_ node_id : 7|32@0+ (1,0) [0|0] "" Vector__XXX

BO_ 1314 DATA_DISPLAY_CLEAR: 5 Vector__XXX
 SG_ display_id : 39|8@0+ (1,0) [0|0] "" Vector__XXX
 SG_ node_id : 7|32@0+ (1,0) [0|0] "" Vector__XXX

BO_ 1315 DATA_DISPLAY_MODE: 6 Vector__XXX
 SG_ flash_rate : 47|8@0+ (1,0) [0|0] "" Vector__XXX
 SG_ display_id : 39|8@0+ (1,0) [0|0] "" Vector__XXX
 SG_ node_id : 7|32@0+ (1,0) [0|0] "" Vector__XXX

BO_ 1316 DATA_ARGB_BUTTON_COLOR: 6 Vector__XXX
 SG_ color_index : 47|8@0+ (1,0) [0|0] "" Vector__XXX
 SG_ button_id : 39|8@0+ (1,0) [0|0] "" Vector__XXX
 SG_ node_id : 7|32@0+ (1,0) [0|0] "" Vector__XXX

BO_ 1317 DATA_ARGB_BUTTON_LED_MODE: 7 Vector__XXX
 SG_ led_mode : 47|16@0+ (1,0) [0|0] "" Vector__XXX
 SG_ button_id : 39|8@0+ (1,0) [0|0] "" Vector__XXX
 SG_ node_id : 7|32@0+ (1,0) [0|0] "" Vector__XXX

BO_ 1318 DATA_CONFIG_CRC: 6 Vector__XXX
 SG_ crc_16 : 39|16@0+ (1,0) [0|0] "" Vector__XXX
 SG_ node_id : 7|32@0+ (1,0) [0|0] "" Vector__XXX

BO_ 1319 DATA_CONFIG_TIMESTAMP: 8 Vector__XXX
 SG_ unixtime : 39|32@0+ (1,0) [0|0] "" Vector__XXX
 SG_ node_id : 7|32@0+ (1,0) [0|0] "" Vector__XXX

BO_ 1320 DATA_CFGWRITE_FAILED: 6 Vector__XXX
 SG_ crc_16 : 39|16@0+ (1,0) [0|0] "" Vector__XXX
 SG_ node_id : 7|32@0+ (1,0) [0|0] "" Vector__XXX

BO_ 1321 DATA_RESERVED_529: 4 Vector__XXX
 SG_ node_id : 7|32@0+ (1,0) [0|0] "" Vector__XXX

BO_ 1322 DATA_RESERVED_52A: 8 Vector__XXX
 SG_ sensor_data : 7|64@0+ (1,0) [0|0] "" Vector__XXX

BO_ 1323 DATA_RESERVED_52B: 8 Vector__XXX
 SG_ sensor_data : 7|64@0+ (1,0) [0|0] "" Vector__XXX

BO_ 1324 DATA_RESERVED_52C: 8 Vector__XXX
 SG_ sensor_data : 7|64@0+ (1,0) [0|0] "" Vector__XXX

BO_ 1325 DATA_RESERVED_52D: 8 Vector__XXX
 SG_ sensor_data : 7|64@0+ (1,0) [0|0] "" Vector__XXX

BO_ 1326 DATA_RESERVED_52E: 8 Vector__XXX
 SG_ sensor_data : 7|64@0+ (1,0) [0|0] "" Vector__XXX

BO_ 1327 DATA_RESERVED_52F: 8 Vector__XXX
 SG_ sensor_data : 7|64@0+ (1,0) [0|0] "" Vector__XXX

BO_ 1328 DATA_RESERVED_530: 8 Vector__XXX
 SG_ sensor_data : 7|64@0+ (1,0) [0|0] "" Vector__XXX

BO_ 1329 DATA_RESERVED_531: 8 Vector__XXX
 SG_ sensor_data : 7|64@0+ (1,0) [0|0] "" Vector__XXX

BO_ 1330 DATA_RESERVED_532: 8 Vector__XXX
 SG_ sensor_data : 7|64@0+ (1,0) [0|0] "" Vector__XXX

BO_ 1331 DATA_RESERVED_533: 8 Vector__XXX
 SG_ sensor_data : 7|64@0+ (1,0) [0|0] "" Vector__XXX

BO_ 1332 DATA_RESERVED_534: 8 Vector__XXX
 SG_ sensor_data : 7|64@0+ (1,0) [0|0] "" Vector__XXX

BO_ 1333 DATA_RESERVED_535: 8 Vector__XXX
 SG_ sensor_data : 7|64@0+ (1,0) [0|0] "" Vector__XXX

BO_ 1334 DATA_RESERVED_536: 8 Vector__XXX
 SG_ sensor_data : 7|64@0+ (1,0) [0|0] "" Vector__XXX

BO_ 1335 DATA_RESERVED_537: 8 Vector__XXX
 SG_ sensor_data : 7|64@0+ (1,0) [0|0] "" Vector__XXX

BO_ 1336 DATA_RESERVED_538: 8 Vector__XXX
 SG_ sensor_data : 7|64@0+ (1,0) [0|0] "" Vector__XXX

BO_ 1337 DATA_RESERVED_539: 8 Vector__XXX
 SG_ sensor_data : 7|64@0+ (1,0) [0|0] "" Vector__XXX

BO_ 1338 DATA_RESERVED_53A: 8 Vector__XXX
 SG_ sensor_data : 7|64@0+ (1,0) [0|0] "" Vector__XXX

BO_ 1339 DATA_RESERVED_53B: 8 Vector__XXX
 SG_ sensor_data : 7|64@0+ (1,0) [0|0] "" Vector__XXX

BO_ 1340 DATA_RESERVED_53C: 8 Vector__XXX
 SG_ sensor_data : 7|64@0+ (1,0) [0|0] "" Vector__XXX

BO_ 1341 DATA_RESERVED_53D: 8 Vector__XXX
 SG_ sensor_data : 7|64@0+ (1,0) [0|0] "" Vector__XXX

BO_ 1342 DATA_RESERVED_53E: 8 Vector__XXX
 SG_ sensor_data : 7|64@0+ (1,0) [0|0] "" Vector__XXX

BO_ 1343 DATA_RESERVED_53F: 8 Vector__XXX
 SG_ sensor_data : 7|64@0+ (1,0) [0|0] "" Vector__XXX

BO_ 1792 DISP_ANALOG_LED_STRIP: 8 Vector__XXX
 SG_ config_2 : 63|8@0+ (1,0) [0|0] "" Vector__XXX
 SG_ config_1 : 55|8@0+ (1,0) [0|0] "" Vector__XXX
 SG_ config_0 : 47|8@0+ (1,0) [0|0] "" Vector__XXX
 SG_ sub_module_index : 39|8@0+ (1,0) [0|0] "" Vector__XXX
 SG_ node_id : 7|32@0+ (1,0) [0|0] "" Vector__XXX

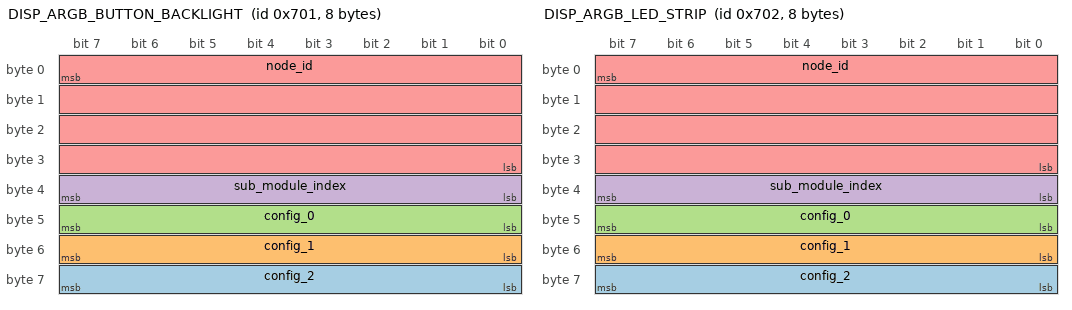
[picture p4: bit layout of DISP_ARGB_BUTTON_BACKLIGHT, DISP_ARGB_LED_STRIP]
BO_ 1793 DISP_ARGB_BUTTON_BACKLIGHT: 8 Vector__XXX
 SG_ config_2 : 63|8@0+ (1,0) [0|0] "" Vector__XXX
 SG_ config_1 : 55|8@0+ (1,0) [0|0] "" Vector__XXX
 SG_ config_0 : 47|8@0+ (1,0) [0|0] "" Vector__XXX
 SG_ sub_module_index : 39|8@0+ (1,0) [0|0] "" Vector__XXX
 SG_ node_id : 7|32@0+ (1,0) [0|0] "" Vector__XXX

BO_ 1794 DISP_ARGB_LED_STRIP: 8 Vector__XXX
 SG_ config_2 : 63|8@0+ (1,0) [0|0] "" Vector__XXX
 SG_ config_1 : 55|8@0+ (1,0) [0|0] "" Vector__XXX
 SG_ config_0 : 47|8@0+ (1,0) [0|0] "" Vector__XXX
 SG_ sub_module_index : 39|8@0+ (1,0) [0|0] "" Vector__XXX
 SG_ node_id : 7|32@0+ (1,0) [0|0] "" Vector__XXX

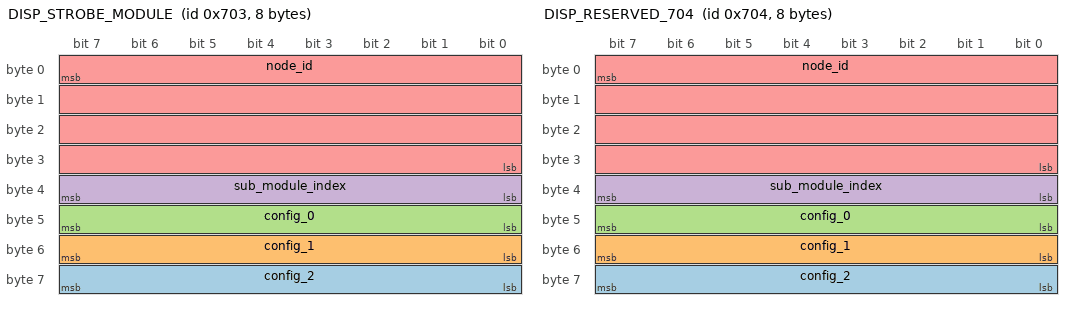
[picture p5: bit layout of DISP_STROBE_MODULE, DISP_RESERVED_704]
BO_ 1795 DISP_STROBE_MODULE: 8 Vector__XXX
 SG_ config_2 : 63|8@0+ (1,0) [0|0] "" Vector__XXX
 SG_ config_1 : 55|8@0+ (1,0) [0|0] "" Vector__XXX
 SG_ config_0 : 47|8@0+ (1,0) [0|0] "" Vector__XXX
 SG_ sub_module_index : 39|8@0+ (1,0) [0|0] "" Vector__XXX
 SG_ node_id : 7|32@0+ (1,0) [0|0] "" Vector__XXX

BO_ 1796 DISP_RESERVED_704: 8 Vector__XXX
 SG_ config_2 : 63|8@0+ (1,0) [0|0] "" Vector__XXX
 SG_ config_1 : 55|8@0+ (1,0) [0|0] "" Vector__XXX
 SG_ config_0 : 47|8@0+ (1,0) [0|0] "" Vector__XXX
 SG_ sub_module_index : 39|8@0+ (1,0) [0|0] "" Vector__XXX
 SG_ node_id : 7|32@0+ (1,0) [0|0] "" Vector__XXX

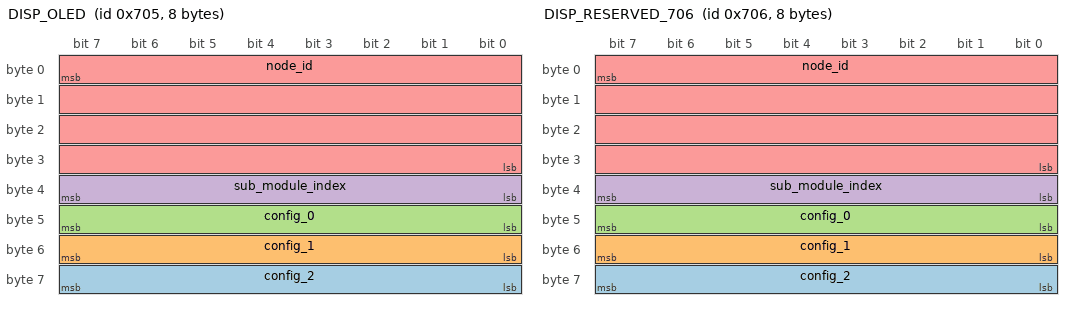
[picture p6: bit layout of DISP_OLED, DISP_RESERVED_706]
BO_ 1797 DISP_OLED: 8 Vector__XXX
 SG_ config_2 : 63|8@0+ (1,0) [0|0] "" Vector__XXX
 SG_ config_1 : 55|8@0+ (1,0) [0|0] "" Vector__XXX
 SG_ config_0 : 47|8@0+ (1,0) [0|0] "" Vector__XXX
 SG_ sub_module_index : 39|8@0+ (1,0) [0|0] "" Vector__XXX
 SG_ node_id : 7|32@0+ (1,0) [0|0] "" Vector__XXX

BO_ 1798 DISP_RESERVED_706: 8 Vector__XXX
 SG_ config_2 : 63|8@0+ (1,0) [0|0] "" Vector__XXX
 SG_ config_1 : 55|8@0+ (1,0) [0|0] "" Vector__XXX
 SG_ config_0 : 47|8@0+ (1,0) [0|0] "" Vector__XXX
 SG_ sub_module_index : 39|8@0+ (1,0) [0|0] "" Vector__XXX
 SG_ node_id : 7|32@0+ (1,0) [0|0] "" Vector__XXX

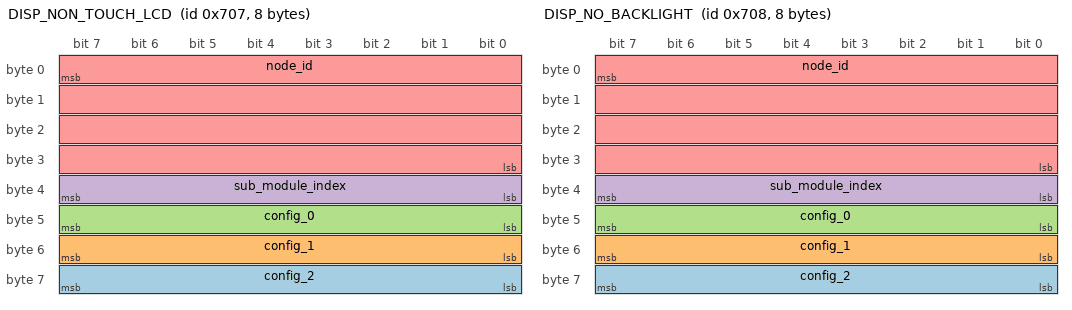
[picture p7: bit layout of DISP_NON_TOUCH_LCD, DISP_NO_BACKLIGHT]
BO_ 1799 DISP_NON_TOUCH_LCD: 8 Vector__XXX
 SG_ config_2 : 63|8@0+ (1,0) [0|0] "" Vector__XXX
 SG_ config_1 : 55|8@0+ (1,0) [0|0] "" Vector__XXX
 SG_ config_0 : 47|8@0+ (1,0) [0|0] "" Vector__XXX
 SG_ sub_module_index : 39|8@0+ (1,0) [0|0] "" Vector__XXX
 SG_ node_id : 7|32@0+ (1,0) [0|0] "" Vector__XXX

BO_ 1800 DISP_NO_BACKLIGHT: 8 Vector__XXX
 SG_ config_2 : 63|8@0+ (1,0) [0|0] "" Vector__XXX
 SG_ config_1 : 55|8@0+ (1,0) [0|0] "" Vector__XXX
 SG_ config_0 : 47|8@0+ (1,0) [0|0] "" Vector__XXX
 SG_ sub_module_index : 39|8@0+ (1,0) [0|0] "" Vector__XXX
 SG_ node_id : 7|32@0+ (1,0) [0|0] "" Vector__XXX

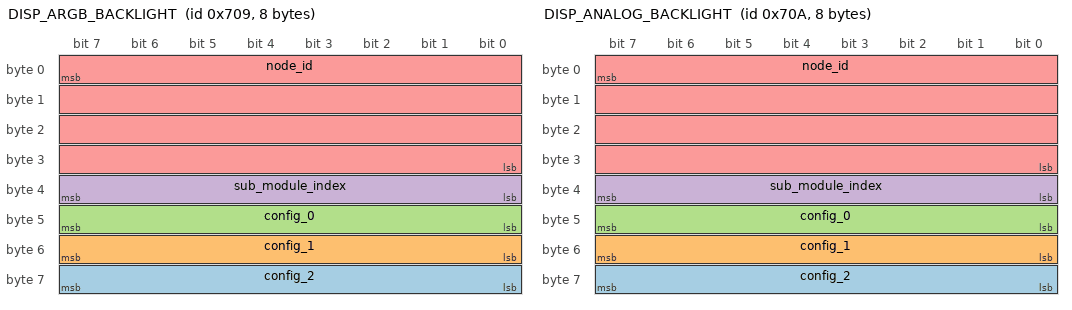
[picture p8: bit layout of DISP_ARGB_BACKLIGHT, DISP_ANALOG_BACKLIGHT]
BO_ 1801 DISP_ARGB_BACKLIGHT: 8 Vector__XXX
 SG_ config_2 : 63|8@0+ (1,0) [0|0] "" Vector__XXX
 SG_ config_1 : 55|8@0+ (1,0) [0|0] "" Vector__XXX
 SG_ config_0 : 47|8@0+ (1,0) [0|0] "" Vector__XXX
 SG_ sub_module_index : 39|8@0+ (1,0) [0|0] "" Vector__XXX
 SG_ node_id : 7|32@0+ (1,0) [0|0] "" Vector__XXX

BO_ 1802 DISP_ANALOG_BACKLIGHT: 8 Vector__XXX
 SG_ config_2 : 63|8@0+ (1,0) [0|0] "" Vector__XXX
 SG_ config_1 : 55|8@0+ (1,0) [0|0] "" Vector__XXX
 SG_ config_0 : 47|8@0+ (1,0) [0|0] "" Vector__XXX
 SG_ sub_module_index : 39|8@0+ (1,0) [0|0] "" Vector__XXX
 SG_ node_id : 7|32@0+ (1,0) [0|0] "" Vector__XXX

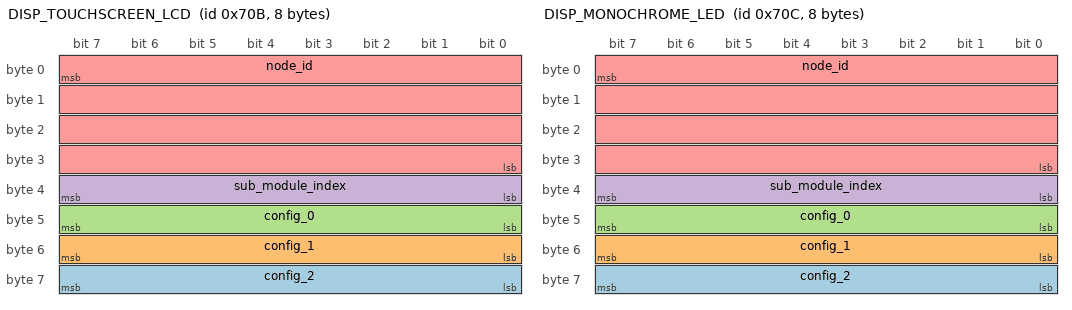
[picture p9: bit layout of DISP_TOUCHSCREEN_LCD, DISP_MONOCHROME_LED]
BO_ 1803 DISP_TOUCHSCREEN_LCD: 8 Vector__XXX
 SG_ config_2 : 63|8@0+ (1,0) [0|0] "" Vector__XXX
 SG_ config_1 : 55|8@0+ (1,0) [0|0] "" Vector__XXX
 SG_ config_0 : 47|8@0+ (1,0) [0|0] "" Vector__XXX
 SG_ sub_module_index : 39|8@0+ (1,0) [0|0] "" Vector__XXX
 SG_ node_id : 7|32@0+ (1,0) [0|0] "" Vector__XXX

BO_ 1804 DISP_MONOCHROME_LED: 8 Vector__XXX
 SG_ config_2 : 63|8@0+ (1,0) [0|0] "" Vector__XXX
 SG_ config_1 : 55|8@0+ (1,0) [0|0] "" Vector__XXX
 SG_ config_0 : 47|8@0+ (1,0) [0|0] "" Vector__XXX
 SG_ sub_module_index : 39|8@0+ (1,0) [0|0] "" Vector__XXX
 SG_ node_id : 7|32@0+ (1,0) [0|0] "" Vector__XXX

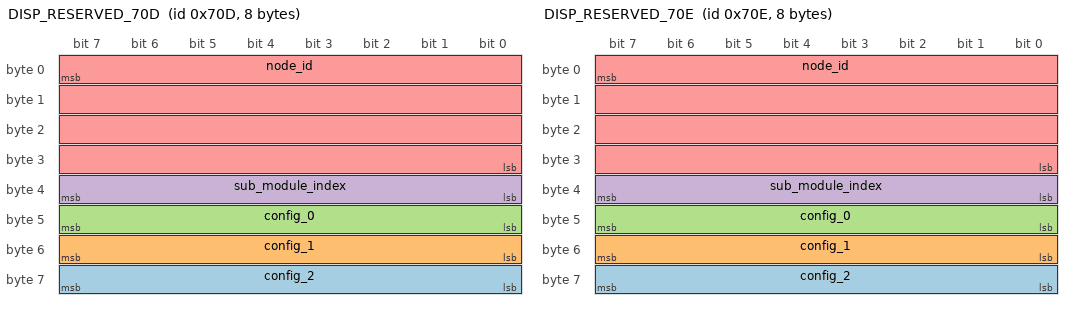
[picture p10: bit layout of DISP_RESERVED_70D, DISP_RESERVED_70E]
BO_ 1805 DISP_RESERVED_70D: 8 Vector__XXX
 SG_ config_2 : 63|8@0+ (1,0) [0|0] "" Vector__XXX
 SG_ config_1 : 55|8@0+ (1,0) [0|0] "" Vector__XXX
 SG_ config_0 : 47|8@0+ (1,0) [0|0] "" Vector__XXX
 SG_ sub_module_index : 39|8@0+ (1,0) [0|0] "" Vector__XXX
 SG_ node_id : 7|32@0+ (1,0) [0|0] "" Vector__XXX

BO_ 1806 DISP_RESERVED_70E: 8 Vector__XXX
 SG_ config_2 : 63|8@0+ (1,0) [0|0] "" Vector__XXX
 SG_ config_1 : 55|8@0+ (1,0) [0|0] "" Vector__XXX
 SG_ config_0 : 47|8@0+ (1,0) [0|0] "" Vector__XXX
 SG_ sub_module_index : 39|8@0+ (1,0) [0|0] "" Vector__XXX
 SG_ node_id : 7|32@0+ (1,0) [0|0] "" Vector__XXX

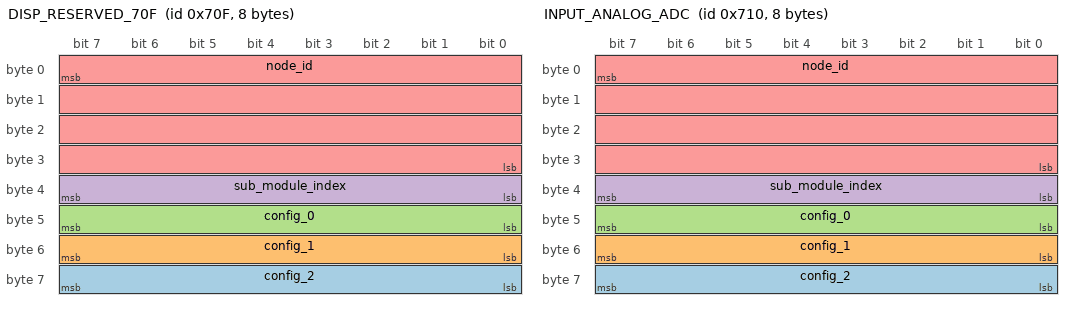
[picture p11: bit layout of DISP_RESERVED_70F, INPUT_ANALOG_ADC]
BO_ 1807 DISP_RESERVED_70F: 8 Vector__XXX
 SG_ config_2 : 63|8@0+ (1,0) [0|0] "" Vector__XXX
 SG_ config_1 : 55|8@0+ (1,0) [0|0] "" Vector__XXX
 SG_ config_0 : 47|8@0+ (1,0) [0|0] "" Vector__XXX
 SG_ sub_module_index : 39|8@0+ (1,0) [0|0] "" Vector__XXX
 SG_ node_id : 7|32@0+ (1,0) [0|0] "" Vector__XXX

BO_ 1808 INPUT_ANALOG_ADC: 8 Vector__XXX
 SG_ config_2 : 63|8@0+ (1,0) [0|0] "" Vector__XXX
 SG_ config_1 : 55|8@0+ (1,0) [0|0] "" Vector__XXX
 SG_ config_0 : 47|8@0+ (1,0) [0|0] "" Vector__XXX
 SG_ sub_module_index : 39|8@0+ (1,0) [0|0] "" Vector__XXX
 SG_ node_id : 7|32@0+ (1,0) [0|0] "" Vector__XXX

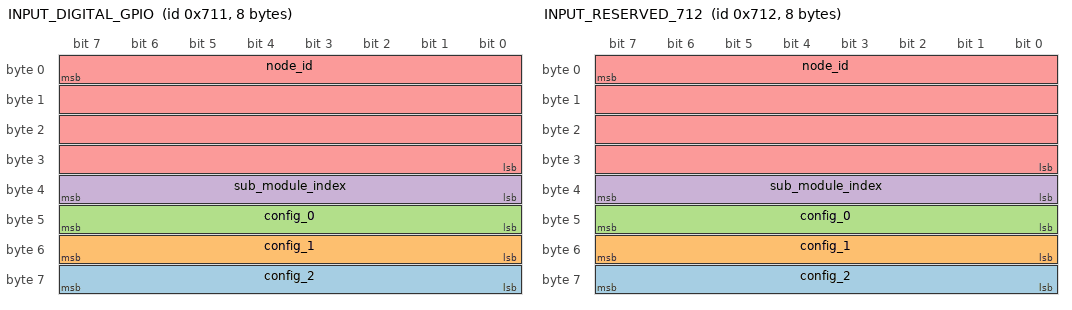
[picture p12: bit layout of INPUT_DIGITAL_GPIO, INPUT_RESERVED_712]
BO_ 1809 INPUT_DIGITAL_GPIO: 8 Vector__XXX
 SG_ config_2 : 63|8@0+ (1,0) [0|0] "" Vector__XXX
 SG_ config_1 : 55|8@0+ (1,0) [0|0] "" Vector__XXX
 SG_ config_0 : 47|8@0+ (1,0) [0|0] "" Vector__XXX
 SG_ sub_module_index : 39|8@0+ (1,0) [0|0] "" Vector__XXX
 SG_ node_id : 7|32@0+ (1,0) [0|0] "" Vector__XXX

BO_ 1810 INPUT_RESERVED_712: 8 Vector__XXX
 SG_ config_2 : 63|8@0+ (1,0) [0|0] "" Vector__XXX
 SG_ config_1 : 55|8@0+ (1,0) [0|0] "" Vector__XXX
 SG_ config_0 : 47|8@0+ (1,0) [0|0] "" Vector__XXX
 SG_ sub_module_index : 39|8@0+ (1,0) [0|0] "" Vector__XXX
 SG_ node_id : 7|32@0+ (1,0) [0|0] "" Vector__XXX

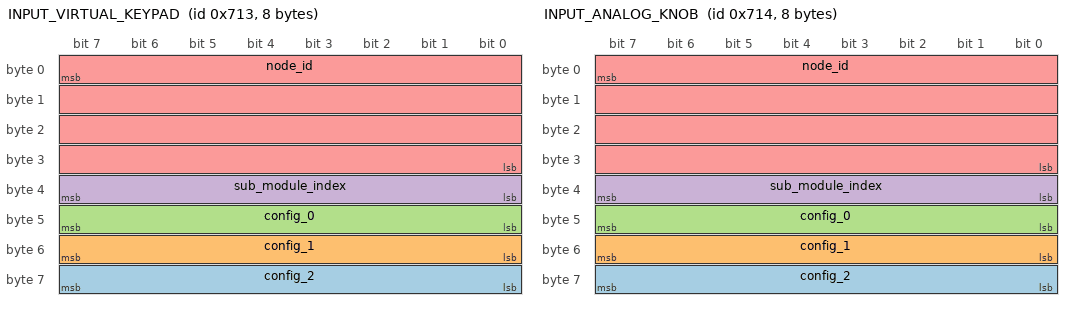
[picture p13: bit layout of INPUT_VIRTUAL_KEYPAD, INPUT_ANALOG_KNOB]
BO_ 1811 INPUT_VIRTUAL_KEYPAD: 8 Vector__XXX
 SG_ config_2 : 63|8@0+ (1,0) [0|0] "" Vector__XXX
 SG_ config_1 : 55|8@0+ (1,0) [0|0] "" Vector__XXX
 SG_ config_0 : 47|8@0+ (1,0) [0|0] "" Vector__XXX
 SG_ sub_module_index : 39|8@0+ (1,0) [0|0] "" Vector__XXX
 SG_ node_id : 7|32@0+ (1,0) [0|0] "" Vector__XXX

BO_ 1812 INPUT_ANALOG_KNOB: 8 Vector__XXX
 SG_ config_2 : 63|8@0+ (1,0) [0|0] "" Vector__XXX
 SG_ config_1 : 55|8@0+ (1,0) [0|0] "" Vector__XXX
 SG_ config_0 : 47|8@0+ (1,0) [0|0] "" Vector__XXX
 SG_ sub_module_index : 39|8@0+ (1,0) [0|0] "" Vector__XXX
 SG_ node_id : 7|32@0+ (1,0) [0|0] "" Vector__XXX

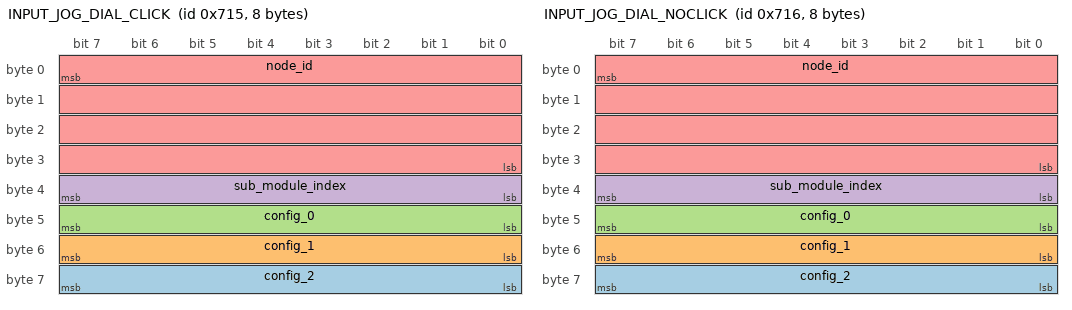
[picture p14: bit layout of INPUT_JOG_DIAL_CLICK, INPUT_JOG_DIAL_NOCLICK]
BO_ 1813 INPUT_JOG_DIAL_CLICK: 8 Vector__XXX
 SG_ config_2 : 63|8@0+ (1,0) [0|0] "" Vector__XXX
 SG_ config_1 : 55|8@0+ (1,0) [0|0] "" Vector__XXX
 SG_ config_0 : 47|8@0+ (1,0) [0|0] "" Vector__XXX
 SG_ sub_module_index : 39|8@0+ (1,0) [0|0] "" Vector__XXX
 SG_ node_id : 7|32@0+ (1,0) [0|0] "" Vector__XXX

BO_ 1814 INPUT_JOG_DIAL_NOCLICK: 8 Vector__XXX
 SG_ config_2 : 63|8@0+ (1,0) [0|0] "" Vector__XXX
 SG_ config_1 : 55|8@0+ (1,0) [0|0] "" Vector__XXX
 SG_ config_0 : 47|8@0+ (1,0) [0|0] "" Vector__XXX
 SG_ sub_module_index : 39|8@0+ (1,0) [0|0] "" Vector__XXX
 SG_ node_id : 7|32@0+ (1,0) [0|0] "" Vector__XXX

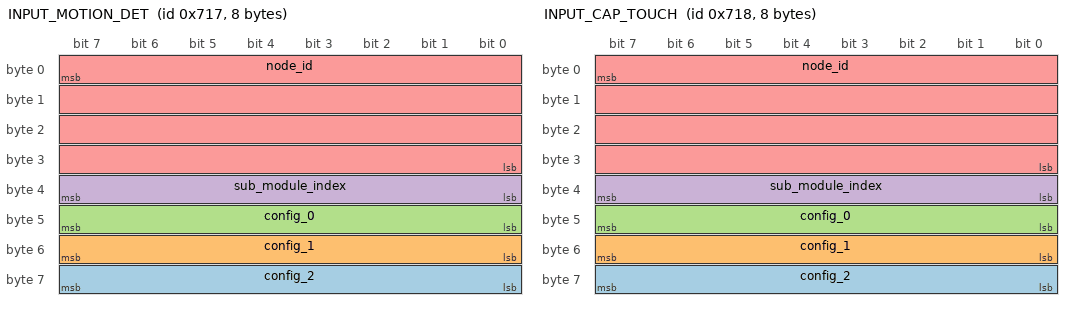
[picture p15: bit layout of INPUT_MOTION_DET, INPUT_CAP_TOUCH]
BO_ 1815 INPUT_MOTION_DET: 8 Vector__XXX
 SG_ config_2 : 63|8@0+ (1,0) [0|0] "" Vector__XXX
 SG_ config_1 : 55|8@0+ (1,0) [0|0] "" Vector__XXX
 SG_ config_0 : 47|8@0+ (1,0) [0|0] "" Vector__XXX
 SG_ sub_module_index : 39|8@0+ (1,0) [0|0] "" Vector__XXX
 SG_ node_id : 7|32@0+ (1,0) [0|0] "" Vector__XXX

BO_ 1816 INPUT_CAP_TOUCH: 8 Vector__XXX
 SG_ config_2 : 63|8@0+ (1,0) [0|0] "" Vector__XXX
 SG_ config_1 : 55|8@0+ (1,0) [0|0] "" Vector__XXX
 SG_ config_0 : 47|8@0+ (1,0) [0|0] "" Vector__XXX
 SG_ sub_module_index : 39|8@0+ (1,0) [0|0] "" Vector__XXX
 SG_ node_id : 7|32@0+ (1,0) [0|0] "" Vector__XXX

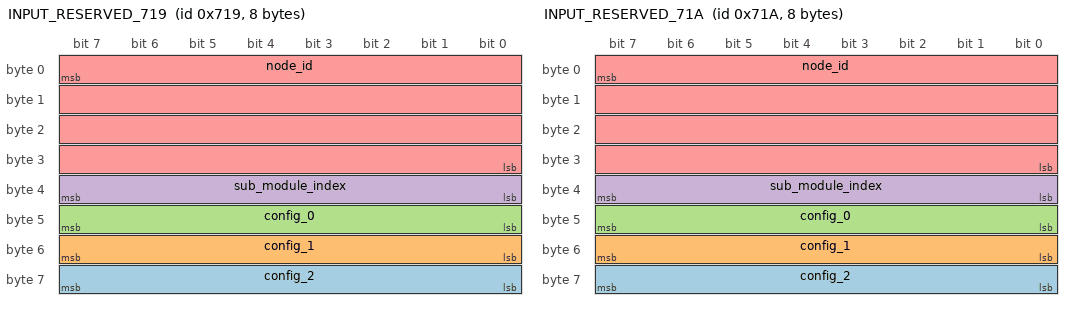
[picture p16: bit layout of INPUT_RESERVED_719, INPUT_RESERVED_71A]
BO_ 1817 INPUT_RESERVED_719: 8 Vector__XXX
 SG_ config_2 : 63|8@0+ (1,0) [0|0] "" Vector__XXX
 SG_ config_1 : 55|8@0+ (1,0) [0|0] "" Vector__XXX
 SG_ config_0 : 47|8@0+ (1,0) [0|0] "" Vector__XXX
 SG_ sub_module_index : 39|8@0+ (1,0) [0|0] "" Vector__XXX
 SG_ node_id : 7|32@0+ (1,0) [0|0] "" Vector__XXX

BO_ 1818 INPUT_RESERVED_71A: 8 Vector__XXX
 SG_ config_2 : 63|8@0+ (1,0) [0|0] "" Vector__XXX
 SG_ config_1 : 55|8@0+ (1,0) [0|0] "" Vector__XXX
 SG_ config_0 : 47|8@0+ (1,0) [0|0] "" Vector__XXX
 SG_ sub_module_index : 39|8@0+ (1,0) [0|0] "" Vector__XXX
 SG_ node_id : 7|32@0+ (1,0) [0|0] "" Vector__XXX

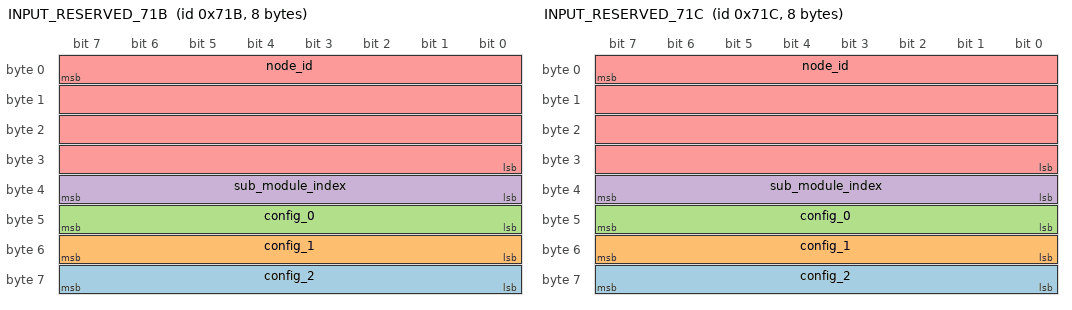
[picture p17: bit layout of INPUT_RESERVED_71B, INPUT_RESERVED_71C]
BO_ 1819 INPUT_RESERVED_71B: 8 Vector__XXX
 SG_ config_2 : 63|8@0+ (1,0) [0|0] "" Vector__XXX
 SG_ config_1 : 55|8@0+ (1,0) [0|0] "" Vector__XXX
 SG_ config_0 : 47|8@0+ (1,0) [0|0] "" Vector__XXX
 SG_ sub_module_index : 39|8@0+ (1,0) [0|0] "" Vector__XXX
 SG_ node_id : 7|32@0+ (1,0) [0|0] "" Vector__XXX

BO_ 1820 INPUT_RESERVED_71C: 8 Vector__XXX
 SG_ config_2 : 63|8@0+ (1,0) [0|0] "" Vector__XXX
 SG_ config_1 : 55|8@0+ (1,0) [0|0] "" Vector__XXX
 SG_ config_0 : 47|8@0+ (1,0) [0|0] "" Vector__XXX
 SG_ sub_module_index : 39|8@0+ (1,0) [0|0] "" Vector__XXX
 SG_ node_id : 7|32@0+ (1,0) [0|0] "" Vector__XXX

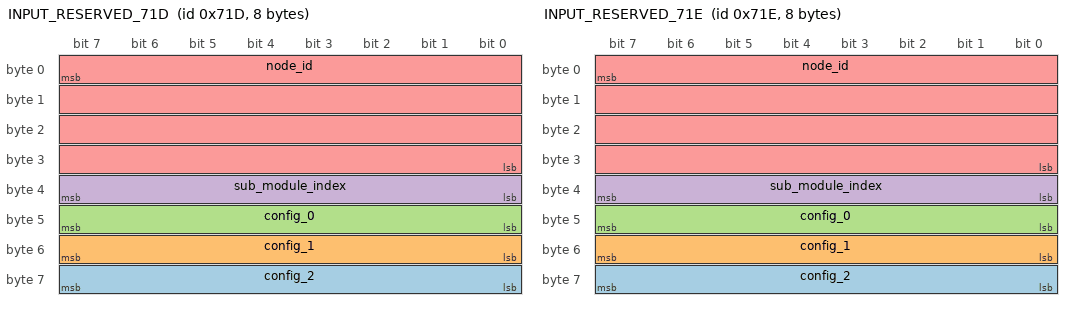
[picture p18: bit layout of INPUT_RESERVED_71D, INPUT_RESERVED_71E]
BO_ 1821 INPUT_RESERVED_71D: 8 Vector__XXX
 SG_ config_2 : 63|8@0+ (1,0) [0|0] "" Vector__XXX
 SG_ config_1 : 55|8@0+ (1,0) [0|0] "" Vector__XXX
 SG_ config_0 : 47|8@0+ (1,0) [0|0] "" Vector__XXX
 SG_ sub_module_index : 39|8@0+ (1,0) [0|0] "" Vector__XXX
 SG_ node_id : 7|32@0+ (1,0) [0|0] "" Vector__XXX

BO_ 1822 INPUT_RESERVED_71E: 8 Vector__XXX
 SG_ config_2 : 63|8@0+ (1,0) [0|0] "" Vector__XXX
 SG_ config_1 : 55|8@0+ (1,0) [0|0] "" Vector__XXX
 SG_ config_0 : 47|8@0+ (1,0) [0|0] "" Vector__XXX
 SG_ sub_module_index : 39|8@0+ (1,0) [0|0] "" Vector__XXX
 SG_ node_id : 7|32@0+ (1,0) [0|0] "" Vector__XXX

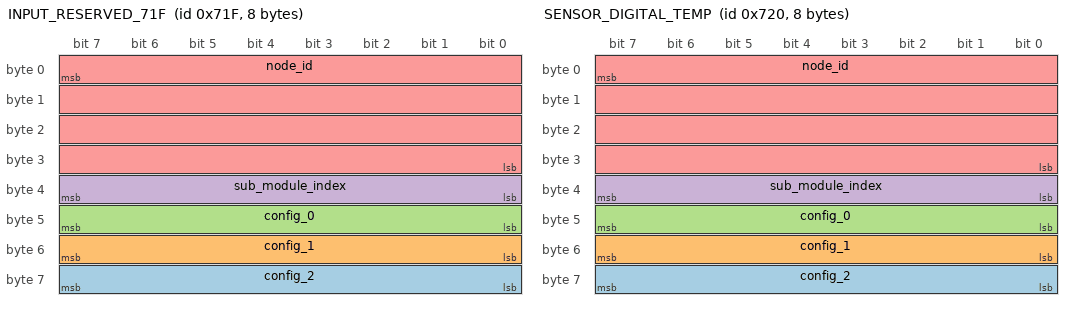
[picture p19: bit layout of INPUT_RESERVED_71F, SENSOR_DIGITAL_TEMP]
BO_ 1823 INPUT_RESERVED_71F: 8 Vector__XXX
 SG_ config_2 : 63|8@0+ (1,0) [0|0] "" Vector__XXX
 SG_ config_1 : 55|8@0+ (1,0) [0|0] "" Vector__XXX
 SG_ config_0 : 47|8@0+ (1,0) [0|0] "" Vector__XXX
 SG_ sub_module_index : 39|8@0+ (1,0) [0|0] "" Vector__XXX
 SG_ node_id : 7|32@0+ (1,0) [0|0] "" Vector__XXX

BO_ 1824 SENSOR_DIGITAL_TEMP: 8 Vector__XXX
 SG_ config_2 : 63|8@0+ (1,0) [0|0] "" Vector__XXX
 SG_ config_1 : 55|8@0+ (1,0) [0|0] "" Vector__XXX
 SG_ config_0 : 47|8@0+ (1,0) [0|0] "" Vector__XXX
 SG_ sub_module_index : 39|8@0+ (1,0) [0|0] "" Vector__XXX
 SG_ node_id : 7|32@0+ (1,0) [0|0] "" Vector__XXX

BO_ 1825 SENSOR_KTYPE_TEMP: 8 Vector__XXX
 SG_ config_2 : 63|8@0+ (1,0) [0|0] "" Vector__XXX
 SG_ config_1 : 55|8@0+ (1,0) [0|0] "" Vector__XXX
 SG_ config_0 : 47|8@0+ (1,0) [0|0] "" Vector__XXX
 SG_ sub_module_index : 39|8@0+ (1,0) [0|0] "" Vector__XXX
 SG_ node_id : 7|32@0+ (1,0) [0|0] "" Vector__XXX

BO_ 1826 SENSOR_NODE_LASTBOOT: 8 Vector__XXX
 SG_ config_2 : 63|8@0+ (1,0) [0|0] "" Vector__XXX
 SG_ config_1 : 55|8@0+ (1,0) [0|0] "" Vector__XXX
 SG_ config_0 : 47|8@0+ (1,0) [0|0] "" Vector__XXX
 SG_ sub_module_index : 39|8@0+ (1,0) [0|0] "" Vector__XXX
 SG_ node_id : 7|32@0+ (1,0) [0|0] "" Vector__XXX

BO_ 1827 SENSOR_NODE_PCB_TEMP: 8 Vector__XXX
 SG_ config_2 : 63|8@0+ (1,0) [0|0] "" Vector__XXX
 SG_ config_1 : 55|8@0+ (1,0) [0|0] "" Vector__XXX
 SG_ config_0 : 47|8@0+ (1,0) [0|0] "" Vector__XXX
 SG_ sub_module_index : 39|8@0+ (1,0) [0|0] "" Vector__XXX
 SG_ node_id : 7|32@0+ (1,0) [0|0] "" Vector__XXX

BO_ 1828 SENSOR_NODE_CPU_TEMP: 8 Vector__XXX
 SG_ config_2 : 63|8@0+ (1,0) [0|0] "" Vector__XXX
 SG_ config_1 : 55|8@0+ (1,0) [0|0] "" Vector__XXX
 SG_ config_0 : 47|8@0+ (1,0) [0|0] "" Vector__XXX
 SG_ sub_module_index : 39|8@0+ (1,0) [0|0] "" Vector__XXX
 SG_ node_id : 7|32@0+ (1,0) [0|0] "" Vector__XXX

BO_ 1829 SENSOR_EXT_VOLTAGE: 8 Vector__XXX
 SG_ config_2 : 63|8@0+ (1,0) [0|0] "" Vector__XXX
 SG_ config_1 : 55|8@0+ (1,0) [0|0] "" Vector__XXX
 SG_ config_0 : 47|8@0+ (1,0) [0|0] "" Vector__XXX
 SG_ sub_module_index : 39|8@0+ (1,0) [0|0] "" Vector__XXX
 SG_ node_id : 7|32@0+ (1,0) [0|0] "" Vector__XXX

BO_ 1830 SENSOR_INT_VOLTAGE: 8 Vector__XXX
 SG_ config_2 : 63|8@0+ (1,0) [0|0] "" Vector__XXX
 SG_ config_1 : 55|8@0+ (1,0) [0|0] "" Vector__XXX
 SG_ config_0 : 47|8@0+ (1,0) [0|0] "" Vector__XXX
 SG_ sub_module_index : 39|8@0+ (1,0) [0|0] "" Vector__XXX
 SG_ node_id : 7|32@0+ (1,0) [0|0] "" Vector__XXX

BO_ 1831 SENSOR_INT_CURRENT: 8 Vector__XXX
 SG_ config_2 : 63|8@0+ (1,0) [0|0] "" Vector__XXX
 SG_ config_1 : 55|8@0+ (1,0) [0|0] "" Vector__XXX
 SG_ config_0 : 47|8@0+ (1,0) [0|0] "" Vector__XXX
 SG_ sub_module_index : 39|8@0+ (1,0) [0|0] "" Vector__XXX
 SG_ node_id : 7|32@0+ (1,0) [0|0] "" Vector__XXX

BO_ 1832 SENSOR_EXT_CURRENT_SHUNT: 8 Vector__XXX
 SG_ config_2 : 63|8@0+ (1,0) [0|0] "" Vector__XXX
 SG_ config_1 : 55|8@0+ (1,0) [0|0] "" Vector__XXX
 SG_ config_0 : 47|8@0+ (1,0) [0|0] "" Vector__XXX
 SG_ sub_module_index : 39|8@0+ (1,0) [0|0] "" Vector__XXX
 SG_ node_id : 7|32@0+ (1,0) [0|0] "" Vector__XXX

BO_ 1833 SENSOR_EXT_CURRENT_HALL: 8 Vector__XXX
 SG_ config_2 : 63|8@0+ (1,0) [0|0] "" Vector__XXX
 SG_ config_1 : 55|8@0+ (1,0) [0|0] "" Vector__XXX
 SG_ config_0 : 47|8@0+ (1,0) [0|0] "" Vector__XXX
 SG_ sub_module_index : 39|8@0+ (1,0) [0|0] "" Vector__XXX
 SG_ node_id : 7|32@0+ (1,0) [0|0] "" Vector__XXX

BO_ 1834 SENSOR_RESERVED_72A: 8 Vector__XXX
 SG_ config_2 : 63|8@0+ (1,0) [0|0] "" Vector__XXX
 SG_ config_1 : 55|8@0+ (1,0) [0|0] "" Vector__XXX
 SG_ config_0 : 47|8@0+ (1,0) [0|0] "" Vector__XXX
 SG_ sub_module_index : 39|8@0+ (1,0) [0|0] "" Vector__XXX
 SG_ node_id : 7|32@0+ (1,0) [0|0] "" Vector__XXX

BO_ 1835 SENSOR_RESERVED_72B: 8 Vector__XXX
 SG_ config_2 : 63|8@0+ (1,0) [0|0] "" Vector__XXX
 SG_ config_1 : 55|8@0+ (1,0) [0|0] "" Vector__XXX
 SG_ config_0 : 47|8@0+ (1,0) [0|0] "" Vector__XXX
 SG_ sub_module_index : 39|8@0+ (1,0) [0|0] "" Vector__XXX
 SG_ node_id : 7|32@0+ (1,0) [0|0] "" Vector__XXX

BO_ 1836 SENSOR_RESERVED_72C: 8 Vector__XXX
 SG_ config_2 : 63|8@0+ (1,0) [0|0] "" Vector__XXX
 SG_ config_1 : 55|8@0+ (1,0) [0|0] "" Vector__XXX
 SG_ config_0 : 47|8@0+ (1,0) [0|0] "" Vector__XXX
 SG_ sub_module_index : 39|8@0+ (1,0) [0|0] "" Vector__XXX
 SG_ node_id : 7|32@0+ (1,0) [0|0] "" Vector__XXX

BO_ 1837 SENSOR_RESERVED_72D: 8 Vector__XXX
 SG_ config_2 : 63|8@0+ (1,0) [0|0] "" Vector__XXX
 SG_ config_1 : 55|8@0+ (1,0) [0|0] "" Vector__XXX
 SG_ config_0 : 47|8@0+ (1,0) [0|0] "" Vector__XXX
 SG_ sub_module_index : 39|8@0+ (1,0) [0|0] "" Vector__XXX
 SG_ node_id : 7|32@0+ (1,0) [0|0] "" Vector__XXX

BO_ 1838 SENSOR_RESERVED_72E: 8 Vector__XXX
 SG_ config_2 : 63|8@0+ (1,0) [0|0] "" Vector__XXX
 SG_ config_1 : 55|8@0+ (1,0) [0|0] "" Vector__XXX
 SG_ config_0 : 47|8@0+ (1,0) [0|0] "" Vector__XXX
 SG_ sub_module_index : 39|8@0+ (1,0) [0|0] "" Vector__XXX
 SG_ node_id : 7|32@0+ (1,0) [0|0] "" Vector__XXX

BO_ 1839 SENSOR_RESERVED_72F: 8 Vector__XXX
 SG_ config_2 : 63|8@0+ (1,0) [0|0] "" Vector__XXX
 SG_ config_1 : 55|8@0+ (1,0) [0|0] "" Vector__XXX
 SG_ config_0 : 47|8@0+ (1,0) [0|0] "" Vector__XXX
 SG_ sub_module_index : 39|8@0+ (1,0) [0|0] "" Vector__XXX
 SG_ node_id : 7|32@0+ (1,0) [0|0] "" Vector__XXX

BO_ 1840 INPUT_AMBIENT_LIGHT: 8 Vector__XXX
 SG_ config_2 : 63|8@0+ (1,0) [0|0] "" Vector__XXX
 SG_ config_1 : 55|8@0+ (1,0) [0|0] "" Vector__XXX
 SG_ config_0 : 47|8@0+ (1,0) [0|0] "" Vector__XXX
 SG_ sub_module_index : 39|8@0+ (1,0) [0|0] "" Vector__XXX
 SG_ node_id : 7|32@0+ (1,0) [0|0] "" Vector__XXX

BO_ 1841 IMU_X_AXIS_SENSOR: 8 Vector__XXX
 SG_ config_2 : 63|8@0+ (1,0) [0|0] "" Vector__XXX
 SG_ config_1 : 55|8@0+ (1,0) [0|0] "" Vector__XXX
 SG_ config_0 : 47|8@0+ (1,0) [0|0] "" Vector__XXX
 SG_ sub_module_index : 39|8@0+ (1,0) [0|0] "" Vector__XXX
 SG_ node_id : 7|32@0+ (1,0) [0|0] "" Vector__XXX

BO_ 1842 IMU_Y_AXIS_SENSOR: 8 Vector__XXX
 SG_ config_2 : 63|8@0+ (1,0) [0|0] "" Vector__XXX
 SG_ config_1 : 55|8@0+ (1,0) [0|0] "" Vector__XXX
 SG_ config_0 : 47|8@0+ (1,0) [0|0] "" Vector__XXX
 SG_ sub_module_index : 39|8@0+ (1,0) [0|0] "" Vector__XXX
 SG_ node_id : 7|32@0+ (1,0) [0|0] "" Vector__XXX

BO_ 1843 IMU_Z_AXIS_SENSOR: 8 Vector__XXX
 SG_ config_2 : 63|8@0+ (1,0) [0|0] "" Vector__XXX
 SG_ config_1 : 55|8@0+ (1,0) [0|0] "" Vector__XXX
 SG_ config_0 : 47|8@0+ (1,0) [0|0] "" Vector__XXX
 SG_ sub_module_index : 39|8@0+ (1,0) [0|0] "" Vector__XXX
 SG_ node_id : 7|32@0+ (1,0) [0|0] "" Vector__XXX

BO_ 1844 IMU_X_GYRO_SENSOR: 8 Vector__XXX
 SG_ config_2 : 63|8@0+ (1,0) [0|0] "" Vector__XXX
 SG_ config_1 : 55|8@0+ (1,0) [0|0] "" Vector__XXX
 SG_ config_0 : 47|8@0+ (1,0) [0|0] "" Vector__XXX
 SG_ sub_module_index : 39|8@0+ (1,0) [0|0] "" Vector__XXX
 SG_ node_id : 7|32@0+ (1,0) [0|0] "" Vector__XXX

BO_ 1845 IMU_Y_GYRO_SENSOR: 8 Vector__XXX
 SG_ config_2 : 63|8@0+ (1,0) [0|0] "" Vector__XXX
 SG_ config_1 : 55|8@0+ (1,0) [0|0] "" Vector__XXX
 SG_ config_0 : 47|8@0+ (1,0) [0|0] "" Vector__XXX
 SG_ sub_module_index : 39|8@0+ (1,0) [0|0] "" Vector__XXX
 SG_ node_id : 7|32@0+ (1,0) [0|0] "" Vector__XXX

BO_ 1846 IMU_Z_GYRO_SENSOR: 8 Vector__XXX
 SG_ config_2 : 63|8@0+ (1,0) [0|0] "" Vector__XXX
 SG_ config_1 : 55|8@0+ (1,0) [0|0] "" Vector__XXX
 SG_ config_0 : 47|8@0+ (1,0) [0|0] "" Vector__XXX
 SG_ sub_module_index : 39|8@0+ (1,0) [0|0] "" Vector__XXX
 SG_ node_id : 7|32@0+ (1,0) [0|0] "" Vector__XXX

BO_ 1847 IMU_TEMP_SENSOR: 8 Vector__XXX
 SG_ config_2 : 63|8@0+ (1,0) [0|0] "" Vector__XXX
 SG_ config_1 : 55|8@0+ (1,0) [0|0] "" Vector__XXX
 SG_ config_0 : 47|8@0+ (1,0) [0|0] "" Vector__XXX
 SG_ sub_module_index : 39|8@0+ (1,0) [0|0] "" Vector__XXX
 SG_ node_id : 7|32@0+ (1,0) [0|0] "" Vector__XXX

BO_ 1848 GPS_UTC_TIME: 8 Vector__XXX
 SG_ config_2 : 63|8@0+ (1,0) [0|0] "" Vector__XXX
 SG_ config_1 : 55|8@0+ (1,0) [0|0] "" Vector__XXX
 SG_ config_0 : 47|8@0+ (1,0) [0|0] "" Vector__XXX
 SG_ sub_module_index : 39|8@0+ (1,0) [0|0] "" Vector__XXX
 SG_ node_id : 7|32@0+ (1,0) [0|0] "" Vector__XXX

BO_ 1849 GPS_LATITUDE: 8 Vector__XXX
 SG_ config_2 : 63|8@0+ (1,0) [0|0] "" Vector__XXX
 SG_ config_1 : 55|8@0+ (1,0) [0|0] "" Vector__XXX
 SG_ config_0 : 47|8@0+ (1,0) [0|0] "" Vector__XXX
 SG_ sub_module_index : 39|8@0+ (1,0) [0|0] "" Vector__XXX
 SG_ node_id : 7|32@0+ (1,0) [0|0] "" Vector__XXX

BO_ 1850 GPS_NS_IND: 8 Vector__XXX
 SG_ config_2 : 63|8@0+ (1,0) [0|0] "" Vector__XXX
 SG_ config_1 : 55|8@0+ (1,0) [0|0] "" Vector__XXX
 SG_ config_0 : 47|8@0+ (1,0) [0|0] "" Vector__XXX
 SG_ sub_module_index : 39|8@0+ (1,0) [0|0] "" Vector__XXX
 SG_ node_id : 7|32@0+ (1,0) [0|0] "" Vector__XXX

BO_ 1851 GPS_LONGITUDE: 8 Vector__XXX
 SG_ config_2 : 63|8@0+ (1,0) [0|0] "" Vector__XXX
 SG_ config_1 : 55|8@0+ (1,0) [0|0] "" Vector__XXX
 SG_ config_0 : 47|8@0+ (1,0) [0|0] "" Vector__XXX
 SG_ sub_module_index : 39|8@0+ (1,0) [0|0] "" Vector__XXX
 SG_ node_id : 7|32@0+ (1,0) [0|0] "" Vector__XXX

BO_ 1852 GPS_EW_IND: 8 Vector__XXX
 SG_ config_2 : 63|8@0+ (1,0) [0|0] "" Vector__XXX
 SG_ config_1 : 55|8@0+ (1,0) [0|0] "" Vector__XXX
 SG_ config_0 : 47|8@0+ (1,0) [0|0] "" Vector__XXX
 SG_ sub_module_index : 39|8@0+ (1,0) [0|0] "" Vector__XXX
 SG_ node_id : 7|32@0+ (1,0) [0|0] "" Vector__XXX

BO_ 1853 GPS_ALTITUDE: 8 Vector__XXX
 SG_ config_2 : 63|8@0+ (1,0) [0|0] "" Vector__XXX
 SG_ config_1 : 55|8@0+ (1,0) [0|0] "" Vector__XXX
 SG_ config_0 : 47|8@0+ (1,0) [0|0] "" Vector__XXX
 SG_ sub_module_index : 39|8@0+ (1,0) [0|0] "" Vector__XXX
 SG_ node_id : 7|32@0+ (1,0) [0|0] "" Vector__XXX

BO_ 1854 GPS_STATUS: 8 Vector__XXX
 SG_ config_2 : 63|8@0+ (1,0) [0|0] "" Vector__XXX
 SG_ config_1 : 55|8@0+ (1,0) [0|0] "" Vector__XXX
 SG_ config_0 : 47|8@0+ (1,0) [0|0] "" Vector__XXX
 SG_ sub_module_index : 39|8@0+ (1,0) [0|0] "" Vector__XXX
 SG_ node_id : 7|32@0+ (1,0) [0|0] "" Vector__XXX

BO_ 1855 SENSOR2_RESERVED_73F: 8 Vector__XXX
 SG_ config_2 : 63|8@0+ (1,0) [0|0] "" Vector__XXX
 SG_ config_1 : 55|8@0+ (1,0) [0|0] "" Vector__XXX
 SG_ config_0 : 47|8@0+ (1,0) [0|0] "" Vector__XXX
 SG_ sub_module_index : 39|8@0+ (1,0) [0|0] "" Vector__XXX
 SG_ node_id : 7|32@0+ (1,0) [0|0] "" Vector__XXX

BO_ 1856 OUT_HIGH_CURRENT_SW: 8 Vector__XXX
 SG_ config_2 : 63|8@0+ (1,0) [0|0] "" Vector__XXX
 SG_ config_1 : 55|8@0+ (1,0) [0|0] "" Vector__XXX
 SG_ config_0 : 47|8@0+ (1,0) [0|0] "" Vector__XXX
 SG_ sub_module_index : 39|8@0+ (1,0) [0|0] "" Vector__XXX
 SG_ node_id : 7|32@0+ (1,0) [0|0] "" Vector__XXX

BO_ 1857 OUT_LOW_CURRENT_SW: 8 Vector__XXX
 SG_ config_2 : 63|8@0+ (1,0) [0|0] "" Vector__XXX
 SG_ config_1 : 55|8@0+ (1,0) [0|0] "" Vector__XXX
 SG_ config_0 : 47|8@0+ (1,0) [0|0] "" Vector__XXX
 SG_ sub_module_index : 39|8@0+ (1,0) [0|0] "" Vector__XXX
 SG_ node_id : 7|32@0+ (1,0) [0|0] "" Vector__XXX

BO_ 1858 OUT_OPEN_DRAIN: 8 Vector__XXX
 SG_ config_2 : 63|8@0+ (1,0) [0|0] "" Vector__XXX
 SG_ config_1 : 55|8@0+ (1,0) [0|0] "" Vector__XXX
 SG_ config_0 : 47|8@0+ (1,0) [0|0] "" Vector__XXX
 SG_ sub_module_index : 39|8@0+ (1,0) [0|0] "" Vector__XXX
 SG_ node_id : 7|32@0+ (1,0) [0|0] "" Vector__XXX

BO_ 1859 OUT_MECH_RELAY: 8 Vector__XXX
 SG_ config_2 : 63|8@0+ (1,0) [0|0] "" Vector__XXX
 SG_ config_1 : 55|8@0+ (1,0) [0|0] "" Vector__XXX
 SG_ config_0 : 47|8@0+ (1,0) [0|0] "" Vector__XXX
 SG_ sub_module_index : 39|8@0+ (1,0) [0|0] "" Vector__XXX
 SG_ node_id : 7|32@0+ (1,0) [0|0] "" Vector__XXX

BO_ 1860 OUT_GPIO_DIGITAL: 8 Vector__XXX
 SG_ config_2 : 63|8@0+ (1,0) [0|0] "" Vector__XXX
 SG_ config_1 : 55|8@0+ (1,0) [0|0] "" Vector__XXX
 SG_ config_0 : 47|8@0+ (1,0) [0|0] "" Vector__XXX
 SG_ sub_module_index : 39|8@0+ (1,0) [0|0] "" Vector__XXX
 SG_ node_id : 7|32@0+ (1,0) [0|0] "" Vector__XXX

BO_ 1861 OUT_GPIO_PWM: 8 Vector__XXX
 SG_ config_2 : 63|8@0+ (1,0) [0|0] "" Vector__XXX
 SG_ config_1 : 55|8@0+ (1,0) [0|0] "" Vector__XXX
 SG_ config_0 : 47|8@0+ (1,0) [0|0] "" Vector__XXX
 SG_ sub_module_index : 39|8@0+ (1,0) [0|0] "" Vector__XXX
 SG_ node_id : 7|32@0+ (1,0) [0|0] "" Vector__XXX

BO_ 1862 OUT_GPIO_DAC: 8 Vector__XXX
 SG_ config_2 : 63|8@0+ (1,0) [0|0] "" Vector__XXX
 SG_ config_1 : 55|8@0+ (1,0) [0|0] "" Vector__XXX
 SG_ config_0 : 47|8@0+ (1,0) [0|0] "" Vector__XXX
 SG_ sub_module_index : 39|8@0+ (1,0) [0|0] "" Vector__XXX
 SG_ node_id : 7|32@0+ (1,0) [0|0] "" Vector__XXX

BO_ 1863 OUT_RESERVED_747: 8 Vector__XXX
 SG_ config_2 : 63|8@0+ (1,0) [0|0] "" Vector__XXX
 SG_ config_1 : 55|8@0+ (1,0) [0|0] "" Vector__XXX
 SG_ config_0 : 47|8@0+ (1,0) [0|0] "" Vector__XXX
 SG_ sub_module_index : 39|8@0+ (1,0) [0|0] "" Vector__XXX
 SG_ node_id : 7|32@0+ (1,0) [0|0] "" Vector__XXX

BO_ 1864 OUT_RESERVED_748: 8 Vector__XXX
 SG_ config_2 : 63|8@0+ (1,0) [0|0] "" Vector__XXX
 SG_ config_1 : 55|8@0+ (1,0) [0|0] "" Vector__XXX
 SG_ config_0 : 47|8@0+ (1,0) [0|0] "" Vector__XXX
 SG_ sub_module_index : 39|8@0+ (1,0) [0|0] "" Vector__XXX
 SG_ node_id : 7|32@0+ (1,0) [0|0] "" Vector__XXX

BO_ 1865 OUT_RESERVED_749: 8 Vector__XXX
 SG_ config_2 : 63|8@0+ (1,0) [0|0] "" Vector__XXX
 SG_ config_1 : 55|8@0+ (1,0) [0|0] "" Vector__XXX
 SG_ config_0 : 47|8@0+ (1,0) [0|0] "" Vector__XXX
 SG_ sub_module_index : 39|8@0+ (1,0) [0|0] "" Vector__XXX
 SG_ node_id : 7|32@0+ (1,0) [0|0] "" Vector__XXX

BO_ 1866 OUT_RESERVED_74A: 8 Vector__XXX
 SG_ config_2 : 63|8@0+ (1,0) [0|0] "" Vector__XXX
 SG_ config_1 : 55|8@0+ (1,0) [0|0] "" Vector__XXX
 SG_ config_0 : 47|8@0+ (1,0) [0|0] "" Vector__XXX
 SG_ sub_module_index : 39|8@0+ (1,0) [0|0] "" Vector__XXX
 SG_ node_id : 7|32@0+ (1,0) [0|0] "" Vector__XXX

BO_ 1867 OUT_RESERVED_74B: 8 Vector__XXX
 SG_ config_2 : 63|8@0+ (1,0) [0|0] "" Vector__XXX
 SG_ config_1 : 55|8@0+ (1,0) [0|0] "" Vector__XXX
 SG_ config_0 : 47|8@0+ (1,0) [0|0] "" Vector__XXX
 SG_ sub_module_index : 39|8@0+ (1,0) [0|0] "" Vector__XXX
 SG_ node_id : 7|32@0+ (1,0) [0|0] "" Vector__XXX

BO_ 1868 OUT_RESERVED_74C: 8 Vector__XXX
 SG_ config_2 : 63|8@0+ (1,0) [0|0] "" Vector__XXX
 SG_ config_1 : 55|8@0+ (1,0) [0|0] "" Vector__XXX
 SG_ config_0 : 47|8@0+ (1,0) [0|0] "" Vector__XXX
 SG_ sub_module_index : 39|8@0+ (1,0) [0|0] "" Vector__XXX
 SG_ node_id : 7|32@0+ (1,0) [0|0] "" Vector__XXX

BO_ 1869 OUT_RESERVED_74D: 8 Vector__XXX
 SG_ config_2 : 63|8@0+ (1,0) [0|0] "" Vector__XXX
 SG_ config_1 : 55|8@0+ (1,0) [0|0] "" Vector__XXX
 SG_ config_0 : 47|8@0+ (1,0) [0|0] "" Vector__XXX
 SG_ sub_module_index : 39|8@0+ (1,0) [0|0] "" Vector__XXX
 SG_ node_id : 7|32@0+ (1,0) [0|0] "" Vector__XXX

BO_ 1870 OUT_RESERVED_74E: 8 Vector__XXX
 SG_ config_2 : 63|8@0+ (1,0) [0|0] "" Vector__XXX
 SG_ config_1 : 55|8@0+ (1,0) [0|0] "" Vector__XXX
 SG_ config_0 : 47|8@0+ (1,0) [0|0] "" Vector__XXX
 SG_ sub_module_index : 39|8@0+ (1,0) [0|0] "" Vector__XXX
 SG_ node_id : 7|32@0+ (1,0) [0|0] "" Vector__XXX

BO_ 1871 OUT_RESERVED_74F: 8 Vector__XXX
 SG_ config_2 : 63|8@0+ (1,0) [0|0] "" Vector__XXX
 SG_ config_1 : 55|8@0+ (1,0) [0|0] "" Vector__XXX
 SG_ config_0 : 47|8@0+ (1,0) [0|0] "" Vector__XXX
 SG_ sub_module_index : 39|8@0+ (1,0) [0|0] "" Vector__XXX
 SG_ node_id : 7|32@0+ (1,0) [0|0] "" Vector__XXX

BO_ 1872 INTRO_RESERVED_750: 8 Vector__XXX
 SG_ reserved : 63|8@0+ (1,0) [0|0] "" Vector__XXX
 SG_ crc16 : 47|16@0+ (1,0) [0|0] "" Vector__XXX
 SG_ sub_module_index : 39|8@0+ (1,0) [0|0] "" Vector__XXX
 SG_ node_id : 7|32@0+ (1,0) [0|0] "" Vector__XXX

BO_ 1873 INTRO_RESERVED_751: 8 Vector__XXX
 SG_ reserved : 63|8@0+ (1,0) [0|0] "" Vector__XXX
 SG_ crc16 : 47|16@0+ (1,0) [0|0] "" Vector__XXX
 SG_ sub_module_index : 39|8@0+ (1,0) [0|0] "" Vector__XXX
 SG_ node_id : 7|32@0+ (1,0) [0|0] "" Vector__XXX

BO_ 1874 INTRO_RESERVED_752: 8 Vector__XXX
 SG_ reserved : 63|8@0+ (1,0) [0|0] "" Vector__XXX
 SG_ crc16 : 47|16@0+ (1,0) [0|0] "" Vector__XXX
 SG_ sub_module_index : 39|8@0+ (1,0) [0|0] "" Vector__XXX
 SG_ node_id : 7|32@0+ (1,0) [0|0] "" Vector__XXX

BO_ 1875 INTRO_RESERVED_753: 8 Vector__XXX
 SG_ reserved : 63|8@0+ (1,0) [0|0] "" Vector__XXX
 SG_ crc16 : 47|16@0+ (1,0) [0|0] "" Vector__XXX
 SG_ sub_module_index : 39|8@0+ (1,0) [0|0] "" Vector__XXX
 SG_ node_id : 7|32@0+ (1,0) [0|0] "" Vector__XXX

BO_ 1876 INTRO_RESERVED_754: 8 Vector__XXX
 SG_ reserved : 63|8@0+ (1,0) [0|0] "" Vector__XXX
 SG_ crc16 : 47|16@0+ (1,0) [0|0] "" Vector__XXX
 SG_ sub_module_index : 39|8@0+ (1,0) [0|0] "" Vector__XXX
 SG_ node_id : 7|32@0+ (1,0) [0|0] "" Vector__XXX

BO_ 1877 INTRO_RESERVED_755: 8 Vector__XXX
 SG_ reserved : 63|8@0+ (1,0) [0|0] "" Vector__XXX
 SG_ crc16 : 47|16@0+ (1,0) [0|0] "" Vector__XXX
 SG_ sub_module_index : 39|8@0+ (1,0) [0|0] "" Vector__XXX
 SG_ node_id : 7|32@0+ (1,0) [0|0] "" Vector__XXX

BO_ 1878 INTRO_RESERVED_756: 8 Vector__XXX
 SG_ reserved : 63|8@0+ (1,0) [0|0] "" Vector__XXX
 SG_ crc16 : 47|16@0+ (1,0) [0|0] "" Vector__XXX
 SG_ sub_module_index : 39|8@0+ (1,0) [0|0] "" Vector__XXX
 SG_ node_id : 7|32@0+ (1,0) [0|0] "" Vector__XXX

BO_ 1879 INTRO_RESERVED_757: 8 Vector__XXX
 SG_ reserved : 63|8@0+ (1,0) [0|0] "" Vector__XXX
 SG_ crc16 : 47|16@0+ (1,0) [0|0] "" Vector__XXX
 SG_ sub_module_index : 39|8@0+ (1,0) [0|0] "" Vector__XXX
 SG_ node_id : 7|32@0+ (1,0) [0|0] "" Vector__XXX

BO_ 1880 INTRO_RESERVED_758: 8 Vector__XXX
 SG_ reserved : 63|8@0+ (1,0) [0|0] "" Vector__XXX
 SG_ crc16 : 47|16@0+ (1,0) [0|0] "" Vector__XXX
 SG_ sub_module_index : 39|8@0+ (1,0) [0|0] "" Vector__XXX
 SG_ node_id : 7|32@0+ (1,0) [0|0] "" Vector__XXX

BO_ 1881 INTRO_RESERVED_759: 8 Vector__XXX
 SG_ reserved : 63|8@0+ (1,0) [0|0] "" Vector__XXX
 SG_ crc16 : 47|16@0+ (1,0) [0|0] "" Vector__XXX
 SG_ sub_module_index : 39|8@0+ (1,0) [0|0] "" Vector__XXX
 SG_ node_id : 7|32@0+ (1,0) [0|0] "" Vector__XXX

BO_ 1882 INTRO_RESERVED_75A: 8 Vector__XXX
 SG_ reserved : 63|8@0+ (1,0) [0|0] "" Vector__XXX
 SG_ crc16 : 47|16@0+ (1,0) [0|0] "" Vector__XXX
 SG_ sub_module_index : 39|8@0+ (1,0) [0|0] "" Vector__XXX
 SG_ node_id : 7|32@0+ (1,0) [0|0] "" Vector__XXX

BO_ 1883 INTRO_RESERVED_75B: 8 Vector__XXX
 SG_ reserved : 63|8@0+ (1,0) [0|0] "" Vector__XXX
 SG_ crc16 : 47|16@0+ (1,0) [0|0] "" Vector__XXX
 SG_ sub_module_index : 39|8@0+ (1,0) [0|0] "" Vector__XXX
 SG_ node_id : 7|32@0+ (1,0) [0|0] "" Vector__XXX

BO_ 1884 INTRO_RESERVED_75C: 8 Vector__XXX
 SG_ reserved : 63|8@0+ (1,0) [0|0] "" Vector__XXX
 SG_ crc16 : 47|16@0+ (1,0) [0|0] "" Vector__XXX
 SG_ sub_module_index : 39|8@0+ (1,0) [0|0] "" Vector__XXX
 SG_ node_id : 7|32@0+ (1,0) [0|0] "" Vector__XXX

BO_ 1885 INTRO_RESERVED_75D: 8 Vector__XXX
 SG_ reserved : 63|8@0+ (1,0) [0|0] "" Vector__XXX
 SG_ crc16 : 47|16@0+ (1,0) [0|0] "" Vector__XXX
 SG_ sub_module_index : 39|8@0+ (1,0) [0|0] "" Vector__XXX
 SG_ node_id : 7|32@0+ (1,0) [0|0] "" Vector__XXX

BO_ 1886 INTRO_RESERVED_75E: 8 Vector__XXX
 SG_ reserved : 63|8@0+ (1,0) [0|0] "" Vector__XXX
 SG_ crc16 : 47|16@0+ (1,0) [0|0] "" Vector__XXX
 SG_ sub_module_index : 39|8@0+ (1,0) [0|0] "" Vector__XXX
 SG_ node_id : 7|32@0+ (1,0) [0|0] "" Vector__XXX

BO_ 1887 INTRO_RESERVED_75F: 8 Vector__XXX
 SG_ reserved : 63|8@0+ (1,0) [0|0] "" Vector__XXX
 SG_ crc16 : 47|16@0+ (1,0) [0|0] "" Vector__XXX
 SG_ sub_module_index : 39|8@0+ (1,0) [0|0] "" Vector__XXX
 SG_ node_id : 7|32@0+ (1,0) [0|0] "" Vector__XXX

BO_ 1888 SYS_RESERVED_760: 8 Vector__XXX
 SG_ reserved : 63|8@0+ (1,0) [0|0] "" Vector__XXX
 SG_ crc16 : 47|16@0+ (1,0) [0|0] "" Vector__XXX
 SG_ sub_module_index : 39|8@0+ (1,0) [0|0] "" Vector__XXX
 SG_ node_id : 7|32@0+ (1,0) [0|0] "" Vector__XXX

BO_ 1889 SYS_RESERVED_761: 8 Vector__XXX
 SG_ reserved : 63|8@0+ (1,0) [0|0] "" Vector__XXX
 SG_ crc16 : 47|16@0+ (1,0) [0|0] "" Vector__XXX
 SG_ sub_module_index : 39|8@0+ (1,0) [0|0] "" Vector__XXX
 SG_ node_id : 7|32@0+ (1,0) [0|0] "" Vector__XXX

BO_ 1890 SYS_RESERVED_762: 8 Vector__XXX
 SG_ reserved : 63|8@0+ (1,0) [0|0] "" Vector__XXX
 SG_ crc16 : 47|16@0+ (1,0) [0|0] "" Vector__XXX
 SG_ sub_module_index : 39|8@0+ (1,0) [0|0] "" Vector__XXX
 SG_ node_id : 7|32@0+ (1,0) [0|0] "" Vector__XXX

BO_ 1891 SYS_RESERVED_763: 8 Vector__XXX
 SG_ reserved : 63|8@0+ (1,0) [0|0] "" Vector__XXX
 SG_ crc16 : 47|16@0+ (1,0) [0|0] "" Vector__XXX
 SG_ sub_module_index : 39|8@0+ (1,0) [0|0] "" Vector__XXX
 SG_ node_id : 7|32@0+ (1,0) [0|0] "" Vector__XXX

BO_ 1892 SYS_RESERVED_764: 8 Vector__XXX
 SG_ reserved : 63|8@0+ (1,0) [0|0] "" Vector__XXX
 SG_ crc16 : 47|16@0+ (1,0) [0|0] "" Vector__XXX
 SG_ sub_module_index : 39|8@0+ (1,0) [0|0] "" Vector__XXX
 SG_ node_id : 7|32@0+ (1,0) [0|0] "" Vector__XXX

BO_ 1893 SYS_RESERVED_765: 8 Vector__XXX
 SG_ reserved : 63|8@0+ (1,0) [0|0] "" Vector__XXX
 SG_ crc16 : 47|16@0+ (1,0) [0|0] "" Vector__XXX
 SG_ sub_module_index : 39|8@0+ (1,0) [0|0] "" Vector__XXX
 SG_ node_id : 7|32@0+ (1,0) [0|0] "" Vector__XXX

BO_ 1894 SYS_RESERVED_766: 8 Vector__XXX
 SG_ reserved : 63|8@0+ (1,0) [0|0] "" Vector__XXX
 SG_ crc16 : 47|16@0+ (1,0) [0|0] "" Vector__XXX
 SG_ sub_module_index : 39|8@0+ (1,0) [0|0] "" Vector__XXX
 SG_ node_id : 7|32@0+ (1,0) [0|0] "" Vector__XXX

BO_ 1895 SYS_RESERVED_767: 8 Vector__XXX
 SG_ reserved : 63|8@0+ (1,0) [0|0] "" Vector__XXX
 SG_ crc16 : 47|16@0+ (1,0) [0|0] "" Vector__XXX
 SG_ sub_module_index : 39|8@0+ (1,0) [0|0] "" Vector__XXX
 SG_ node_id : 7|32@0+ (1,0) [0|0] "" Vector__XXX

BO_ 1896 SYS_RESERVED_768: 8 Vector__XXX
 SG_ reserved : 63|8@0+ (1,0) [0|0] "" Vector__XXX
 SG_ crc16 : 47|16@0+ (1,0) [0|0] "" Vector__XXX
 SG_ sub_module_index : 39|8@0+ (1,0) [0|0] "" Vector__XXX
 SG_ node_id : 7|32@0+ (1,0) [0|0] "" Vector__XXX

BO_ 1897 SYS_RESERVED_769: 8 Vector__XXX
 SG_ reserved : 63|8@0+ (1,0) [0|0] "" Vector__XXX
 SG_ crc16 : 47|16@0+ (1,0) [0|0] "" Vector__XXX
 SG_ sub_module_index : 39|8@0+ (1,0) [0|0] "" Vector__XXX
 SG_ node_id : 7|32@0+ (1,0) [0|0] "" Vector__XXX

BO_ 1898 SYS_RESERVED_76A: 8 Vector__XXX
 SG_ reserved : 63|8@0+ (1,0) [0|0] "" Vector__XXX
 SG_ crc16 : 47|16@0+ (1,0) [0|0] "" Vector__XXX
 SG_ sub_module_index : 39|8@0+ (1,0) [0|0] "" Vector__XXX
 SG_ node_id : 7|32@0+ (1,0) [0|0] "" Vector__XXX

BO_ 1899 SYS_RESERVED_76B: 8 Vector__XXX
 SG_ reserved : 63|8@0+ (1,0) [0|0] "" Vector__XXX
 SG_ crc16 : 47|16@0+ (1,0) [0|0] "" Vector__XXX
 SG_ sub_module_index : 39|8@0+ (1,0) [0|0] "" Vector__XXX
 SG_ node_id : 7|32@0+ (1,0) [0|0] "" Vector__XXX

BO_ 1900 SYS_RESERVED_76C: 8 Vector__XXX
 SG_ reserved : 63|8@0+ (1,0) [0|0] "" Vector__XXX
 SG_ crc16 : 47|16@0+ (1,0) [0|0] "" Vector__XXX
 SG_ sub_module_index : 39|8@0+ (1,0) [0|0] "" Vector__XXX
 SG_ node_id : 7|32@0+ (1,0) [0|0] "" Vector__XXX

BO_ 1901 SYS_RESERVED_76D: 8 Vector__XXX
 SG_ reserved : 63|8@0+ (1,0) [0|0] "" Vector__XXX
 SG_ crc16 : 47|16@0+ (1,0) [0|0] "" Vector__XXX
 SG_ sub_module_index : 39|8@0+ (1,0) [0|0] "" Vector__XXX
 SG_ node_id : 7|32@0+ (1,0) [0|0] "" Vector__XXX

BO_ 1902 SYS_RESERVED_76E: 8 Vector__XXX
 SG_ reserved : 63|8@0+ (1,0) [0|0] "" Vector__XXX
 SG_ crc16 : 47|16@0+ (1,0) [0|0] "" Vector__XXX
 SG_ sub_module_index : 39|8@0+ (1,0) [0|0] "" Vector__XXX
 SG_ node_id : 7|32@0+ (1,0) [0|0] "" Vector__XXX

BO_ 1903 SYS_RESERVED_76F: 8 Vector__XXX
 SG_ reserved : 63|8@0+ (1,0) [0|0] "" Vector__XXX
 SG_ crc16 : 47|16@0+ (1,0) [0|0] "" Vector__XXX
 SG_ sub_module_index : 39|8@0+ (1,0) [0|0] "" Vector__XXX
 SG_ node_id : 7|32@0+ (1,0) [0|0] "" Vector__XXX

BO_ 1904 SYS_RESERVED_770: 8 Vector__XXX
 SG_ reserved : 63|8@0+ (1,0) [0|0] "" Vector__XXX
 SG_ crc16 : 47|16@0+ (1,0) [0|0] "" Vector__XXX
 SG_ sub_module_index : 39|8@0+ (1,0) [0|0] "" Vector__XXX
 SG_ node_id : 7|32@0+ (1,0) [0|0] "" Vector__XXX

BO_ 1905 SYS_RESERVED_771: 8 Vector__XXX
 SG_ reserved : 63|8@0+ (1,0) [0|0] "" Vector__XXX
 SG_ crc16 : 47|16@0+ (1,0) [0|0] "" Vector__XXX
 SG_ sub_module_index : 39|8@0+ (1,0) [0|0] "" Vector__XXX
 SG_ node_id : 7|32@0+ (1,0) [0|0] "" Vector__XXX

BO_ 1906 SYS_RESERVED_772: 8 Vector__XXX
 SG_ reserved : 63|8@0+ (1,0) [0|0] "" Vector__XXX
 SG_ crc16 : 47|16@0+ (1,0) [0|0] "" Vector__XXX
 SG_ sub_module_index : 39|8@0+ (1,0) [0|0] "" Vector__XXX
 SG_ node_id : 7|32@0+ (1,0) [0|0] "" Vector__XXX

BO_ 1907 SYS_RESERVED_773: 8 Vector__XXX
 SG_ reserved : 63|8@0+ (1,0) [0|0] "" Vector__XXX
 SG_ crc16 : 47|16@0+ (1,0) [0|0] "" Vector__XXX
 SG_ sub_module_index : 39|8@0+ (1,0) [0|0] "" Vector__XXX
 SG_ node_id : 7|32@0+ (1,0) [0|0] "" Vector__XXX

BO_ 1908 SYS_RESERVED_774: 8 Vector__XXX
 SG_ reserved : 63|8@0+ (1,0) [0|0] "" Vector__XXX
 SG_ crc16 : 47|16@0+ (1,0) [0|0] "" Vector__XXX
 SG_ sub_module_index : 39|8@0+ (1,0) [0|0] "" Vector__XXX
 SG_ node_id : 7|32@0+ (1,0) [0|0] "" Vector__XXX

BO_ 1909 SYS_RESERVED_775: 8 Vector__XXX
 SG_ reserved : 63|8@0+ (1,0) [0|0] "" Vector__XXX
 SG_ crc16 : 47|16@0+ (1,0) [0|0] "" Vector__XXX
 SG_ sub_module_index : 39|8@0+ (1,0) [0|0] "" Vector__XXX
 SG_ node_id : 7|32@0+ (1,0) [0|0] "" Vector__XXX

BO_ 1910 SYS_RESERVED_776: 8 Vector__XXX
 SG_ reserved : 63|8@0+ (1,0) [0|0] "" Vector__XXX
 SG_ crc16 : 47|16@0+ (1,0) [0|0] "" Vector__XXX
 SG_ sub_module_index : 39|8@0+ (1,0) [0|0] "" Vector__XXX
 SG_ node_id : 7|32@0+ (1,0) [0|0] "" Vector__XXX

BO_ 1911 SYS_RESERVED_777: 8 Vector__XXX
 SG_ reserved : 63|8@0+ (1,0) [0|0] "" Vector__XXX
 SG_ crc16 : 47|16@0+ (1,0) [0|0] "" Vector__XXX
 SG_ sub_module_index : 39|8@0+ (1,0) [0|0] "" Vector__XXX
 SG_ node_id : 7|32@0+ (1,0) [0|0] "" Vector__XXX

BO_ 1912 SYS_RESERVED_778: 8 Vector__XXX
 SG_ reserved : 63|8@0+ (1,0) [0|0] "" Vector__XXX
 SG_ crc16 : 47|16@0+ (1,0) [0|0] "" Vector__XXX
 SG_ sub_module_index : 39|8@0+ (1,0) [0|0] "" Vector__XXX
 SG_ node_id : 7|32@0+ (1,0) [0|0] "" Vector__XXX

BO_ 1913 SYS_RESERVED_779: 8 Vector__XXX
 SG_ reserved : 63|8@0+ (1,0) [0|0] "" Vector__XXX
 SG_ crc16 : 47|16@0+ (1,0) [0|0] "" Vector__XXX
 SG_ sub_module_index : 39|8@0+ (1,0) [0|0] "" Vector__XXX
 SG_ node_id : 7|32@0+ (1,0) [0|0] "" Vector__XXX

BO_ 1914 SYS_RESERVED_77A: 8 Vector__XXX
 SG_ reserved : 63|8@0+ (1,0) [0|0] "" Vector__XXX
 SG_ crc16 : 47|16@0+ (1,0) [0|0] "" Vector__XXX
 SG_ sub_module_index : 39|8@0+ (1,0) [0|0] "" Vector__XXX
 SG_ node_id : 7|32@0+ (1,0) [0|0] "" Vector__XXX

BO_ 1915 SYS_RESERVED_77B: 8 Vector__XXX
 SG_ reserved : 63|8@0+ (1,0) [0|0] "" Vector__XXX
 SG_ crc16 : 47|16@0+ (1,0) [0|0] "" Vector__XXX
 SG_ sub_module_index : 39|8@0+ (1,0) [0|0] "" Vector__XXX
 SG_ node_id : 7|32@0+ (1,0) [0|0] "" Vector__XXX

BO_ 1916 SYS_RESERVED_77C: 8 Vector__XXX
 SG_ reserved : 63|8@0+ (1,0) [0|0] "" Vector__XXX
 SG_ crc16 : 47|16@0+ (1,0) [0|0] "" Vector__XXX
 SG_ sub_module_index : 39|8@0+ (1,0) [0|0] "" Vector__XXX
 SG_ node_id : 7|32@0+ (1,0) [0|0] "" Vector__XXX

BO_ 1917 SYS_RESERVED_77D: 8 Vector__XXX
 SG_ reserved : 63|8@0+ (1,0) [0|0] "" Vector__XXX
 SG_ crc16 : 47|16@0+ (1,0) [0|0] "" Vector__XXX
 SG_ sub_module_index : 39|8@0+ (1,0) [0|0] "" Vector__XXX
 SG_ node_id : 7|32@0+ (1,0) [0|0] "" Vector__XXX

BO_ 1918 SYS_RESERVED_77E: 8 Vector__XXX
 SG_ reserved : 63|8@0+ (1,0) [0|0] "" Vector__XXX
 SG_ crc16 : 47|16@0+ (1,0) [0|0] "" Vector__XXX
 SG_ sub_module_index : 39|8@0+ (1,0) [0|0] "" Vector__XXX
 SG_ node_id : 7|32@0+ (1,0) [0|0] "" Vector__XXX

BO_ 1919 SYS_RESERVED_77F: 8 Vector__XXX
 SG_ reserved : 63|8@0+ (1,0) [0|0] "" Vector__XXX
 SG_ crc16 : 47|16@0+ (1,0) [0|0] "" Vector__XXX
 SG_ sub_module_index : 39|8@0+ (1,0) [0|0] "" Vector__XXX
 SG_ node_id : 7|32@0+ (1,0) [0|0] "" Vector__XXX

BO_ 1920 BOX_SW_3GANG: 8 Vector__XXX
 SG_ reserved : 63|8@0+ (1,0) [0|0] "" Vector__XXX
 SG_ crc16 : 47|16@0+ (1,0) [0|0] "" Vector__XXX
 SG_ submodule_count : 39|8@0+ (1,0) [0|0] "" Vector__XXX
 SG_ node_id : 7|32@0+ (1,0) [0|0] "" Vector__XXX

BO_ 1921 BOX_SW_4GANG: 8 Vector__XXX
 SG_ reserved : 63|8@0+ (1,0) [0|0] "" Vector__XXX
 SG_ crc16 : 47|16@0+ (1,0) [0|0] "" Vector__XXX
 SG_ submodule_count : 39|8@0+ (1,0) [0|0] "" Vector__XXX
 SG_ node_id : 7|32@0+ (1,0) [0|0] "" Vector__XXX

BO_ 1922 BOX_SW_6GANG_HIGH: 8 Vector__XXX
 SG_ reserved : 63|8@0+ (1,0) [0|0] "" Vector__XXX
 SG_ crc16 : 47|16@0+ (1,0) [0|0] "" Vector__XXX
 SG_ submodule_count : 39|8@0+ (1,0) [0|0] "" Vector__XXX
 SG_ node_id : 7|32@0+ (1,0) [0|0] "" Vector__XXX

BO_ 1923 BOX_SW_6GANG_LOW: 8 Vector__XXX
 SG_ reserved : 63|8@0+ (1,0) [0|0] "" Vector__XXX
 SG_ crc16 : 47|16@0+ (1,0) [0|0] "" Vector__XXX
 SG_ submodule_count : 39|8@0+ (1,0) [0|0] "" Vector__XXX
 SG_ node_id : 7|32@0+ (1,0) [0|0] "" Vector__XXX

BO_ 1924 BOX_SW_2GANG_HIGH: 8 Vector__XXX
 SG_ reserved : 63|8@0+ (1,0) [0|0] "" Vector__XXX
 SG_ crc16 : 47|16@0+ (1,0) [0|0] "" Vector__XXX
 SG_ submodule_count : 39|8@0+ (1,0) [0|0] "" Vector__XXX
 SG_ node_id : 7|32@0+ (1,0) [0|0] "" Vector__XXX

BO_ 1925 BOX_SW_2GANG_LOW: 8 Vector__XXX
 SG_ reserved : 63|8@0+ (1,0) [0|0] "" Vector__XXX
 SG_ crc16 : 47|16@0+ (1,0) [0|0] "" Vector__XXX
 SG_ submodule_count : 39|8@0+ (1,0) [0|0] "" Vector__XXX
 SG_ node_id : 7|32@0+ (1,0) [0|0] "" Vector__XXX

BO_ 1926 BOX_MULTI_4XTEMP: 8 Vector__XXX
 SG_ reserved : 63|8@0+ (1,0) [0|0] "" Vector__XXX
 SG_ crc16 : 47|16@0+ (1,0) [0|0] "" Vector__XXX
 SG_ submodule_count : 39|8@0+ (1,0) [0|0] "" Vector__XXX
 SG_ node_id : 7|32@0+ (1,0) [0|0] "" Vector__XXX

BO_ 1927 BOX_SW_4RELAY: 8 Vector__XXX
 SG_ reserved : 63|8@0+ (1,0) [0|0] "" Vector__XXX
 SG_ crc16 : 47|16@0+ (1,0) [0|0] "" Vector__XXX
 SG_ submodule_count : 39|8@0+ (1,0) [0|0] "" Vector__XXX
 SG_ node_id : 7|32@0+ (1,0) [0|0] "" Vector__XXX

BO_ 1928 BOX_MULTI_TVA: 8 Vector__XXX
 SG_ reserved : 63|8@0+ (1,0) [0|0] "" Vector__XXX
 SG_ crc16 : 47|16@0+ (1,0) [0|0] "" Vector__XXX
 SG_ submodule_count : 39|8@0+ (1,0) [0|0] "" Vector__XXX
 SG_ node_id : 7|32@0+ (1,0) [0|0] "" Vector__XXX

BO_ 1929 BOX_SW_8RELAY: 8 Vector__XXX
 SG_ reserved : 63|8@0+ (1,0) [0|0] "" Vector__XXX
 SG_ crc16 : 47|16@0+ (1,0) [0|0] "" Vector__XXX
 SG_ submodule_count : 39|8@0+ (1,0) [0|0] "" Vector__XXX
 SG_ node_id : 7|32@0+ (1,0) [0|0] "" Vector__XXX

BO_ 1930 BOX_MULTI_4X4IO: 8 Vector__XXX
 SG_ reserved : 63|8@0+ (1,0) [0|0] "" Vector__XXX
 SG_ crc16 : 47|16@0+ (1,0) [0|0] "" Vector__XXX
 SG_ submodule_count : 39|8@0+ (1,0) [0|0] "" Vector__XXX
 SG_ node_id : 7|32@0+ (1,0) [0|0] "" Vector__XXX

BO_ 1931 BOX_MULTI_IO: 8 Vector__XXX
 SG_ reserved : 63|8@0+ (1,0) [0|0] "" Vector__XXX
 SG_ crc16 : 47|16@0+ (1,0) [0|0] "" Vector__XXX
 SG_ submodule_count : 39|8@0+ (1,0) [0|0] "" Vector__XXX
 SG_ node_id : 7|32@0+ (1,0) [0|0] "" Vector__XXX

BO_ 1932 BOX_RESERVED_78C: 8 Vector__XXX
 SG_ reserved : 63|8@0+ (1,0) [0|0] "" Vector__XXX
 SG_ crc16 : 47|16@0+ (1,0) [0|0] "" Vector__XXX
 SG_ submodule_count : 39|8@0+ (1,0) [0|0] "" Vector__XXX
 SG_ node_id : 7|32@0+ (1,0) [0|0] "" Vector__XXX

BO_ 1933 BOX_RESERVED_78D: 8 Vector__XXX
 SG_ reserved : 63|8@0+ (1,0) [0|0] "" Vector__XXX
 SG_ crc16 : 47|16@0+ (1,0) [0|0] "" Vector__XXX
 SG_ submodule_count : 39|8@0+ (1,0) [0|0] "" Vector__XXX
 SG_ node_id : 7|32@0+ (1,0) [0|0] "" Vector__XXX

BO_ 1934 BOX_RESERVED_78E: 8 Vector__XXX
 SG_ reserved : 63|8@0+ (1,0) [0|0] "" Vector__XXX
 SG_ crc16 : 47|16@0+ (1,0) [0|0] "" Vector__XXX
 SG_ submodule_count : 39|8@0+ (1,0) [0|0] "" Vector__XXX
 SG_ node_id : 7|32@0+ (1,0) [0|0] "" Vector__XXX

BO_ 1935 BOX_RESERVED_78F: 8 Vector__XXX
 SG_ reserved : 63|8@0+ (1,0) [0|0] "" Vector__XXX
 SG_ crc16 : 47|16@0+ (1,0) [0|0] "" Vector__XXX
 SG_ submodule_count : 39|8@0+ (1,0) [0|0] "" Vector__XXX
 SG_ node_id : 7|32@0+ (1,0) [0|0] "" Vector__XXX

BO_ 1936 IFACE_8X4_ARGB_KEYPAD: 8 Vector__XXX
 SG_ reserved : 63|8@0+ (1,0) [0|0] "" Vector__XXX
 SG_ crc16 : 47|16@0+ (1,0) [0|0] "" Vector__XXX
 SG_ submodule_count : 39|8@0+ (1,0) [0|0] "" Vector__XXX
 SG_ node_id : 7|32@0+ (1,0) [0|0] "" Vector__XXX

BO_ 1937 IFACE_4X4_ARGB_KEYPAD: 8 Vector__XXX
 SG_ reserved : 63|8@0+ (1,0) [0|0] "" Vector__XXX
 SG_ crc16 : 47|16@0+ (1,0) [0|0] "" Vector__XXX
 SG_ submodule_count : 39|8@0+ (1,0) [0|0] "" Vector__XXX
 SG_ node_id : 7|32@0+ (1,0) [0|0] "" Vector__XXX

BO_ 1938 IFACE_TOUCHSCREEN_TYPE_A: 8 Vector__XXX
 SG_ reserved : 63|8@0+ (1,0) [0|0] "" Vector__XXX
 SG_ crc16 : 47|16@0+ (1,0) [0|0] "" Vector__XXX
 SG_ submodule_count : 39|8@0+ (1,0) [0|0] "" Vector__XXX
 SG_ node_id : 7|32@0+ (1,0) [0|0] "" Vector__XXX

BO_ 1939 IFACE_TOUCHSCREEN_TYPE_B: 8 Vector__XXX
 SG_ reserved : 63|8@0+ (1,0) [0|0] "" Vector__XXX
 SG_ crc16 : 47|16@0+ (1,0) [0|0] "" Vector__XXX
 SG_ submodule_count : 39|8@0+ (1,0) [0|0] "" Vector__XXX
 SG_ node_id : 7|32@0+ (1,0) [0|0] "" Vector__XXX

BO_ 1940 IFACE_NEXTION_TYPE_A: 8 Vector__XXX
 SG_ reserved : 63|8@0+ (1,0) [0|0] "" Vector__XXX
 SG_ crc16 : 47|16@0+ (1,0) [0|0] "" Vector__XXX
 SG_ submodule_count : 39|8@0+ (1,0) [0|0] "" Vector__XXX
 SG_ node_id : 7|32@0+ (1,0) [0|0] "" Vector__XXX

BO_ 1941 IFACE_NEXTION_TYPE_B: 8 Vector__XXX
 SG_ reserved : 63|8@0+ (1,0) [0|0] "" Vector__XXX
 SG_ crc16 : 47|16@0+ (1,0) [0|0] "" Vector__XXX
 SG_ submodule_count : 39|8@0+ (1,0) [0|0] "" Vector__XXX
 SG_ node_id : 7|32@0+ (1,0) [0|0] "" Vector__XXX

BO_ 1942 IFACE_RESERVED_796: 8 Vector__XXX
 SG_ reserved : 63|8@0+ (1,0) [0|0] "" Vector__XXX
 SG_ crc16 : 47|16@0+ (1,0) [0|0] "" Vector__XXX
 SG_ submodule_count : 39|8@0+ (1,0) [0|0] "" Vector__XXX
 SG_ node_id : 7|32@0+ (1,0) [0|0] "" Vector__XXX

BO_ 1943 IFACE_RESERVED_797: 8 Vector__XXX
 SG_ reserved : 63|8@0+ (1,0) [0|0] "" Vector__XXX
 SG_ crc16 : 47|16@0+ (1,0) [0|0] "" Vector__XXX
 SG_ submodule_count : 39|8@0+ (1,0) [0|0] "" Vector__XXX
 SG_ node_id : 7|32@0+ (1,0) [0|0] "" Vector__XXX

BO_ 1944 IFACE_RESERVED_798: 8 Vector__XXX
 SG_ reserved : 63|8@0+ (1,0) [0|0] "" Vector__XXX
 SG_ crc16 : 47|16@0+ (1,0) [0|0] "" Vector__XXX
 SG_ submodule_count : 39|8@0+ (1,0) [0|0] "" Vector__XXX
 SG_ node_id : 7|32@0+ (1,0) [0|0] "" Vector__XXX

BO_ 1945 IFACE_6_AXIS_IMU: 8 Vector__XXX
 SG_ reserved : 63|8@0+ (1,0) [0|0] "" Vector__XXX
 SG_ crc16 : 47|16@0+ (1,0) [0|0] "" Vector__XXX
 SG_ submodule_count : 39|8@0+ (1,0) [0|0] "" Vector__XXX
 SG_ node_id : 7|32@0+ (1,0) [0|0] "" Vector__XXX

BO_ 1946 IFACE_3X5_BUTTON_BOX: 8 Vector__XXX
 SG_ reserved : 63|8@0+ (1,0) [0|0] "" Vector__XXX
 SG_ crc16 : 47|16@0+ (1,0) [0|0] "" Vector__XXX
 SG_ submodule_count : 39|8@0+ (1,0) [0|0] "" Vector__XXX
 SG_ node_id : 7|32@0+ (1,0) [0|0] "" Vector__XXX

BO_ 1947 IFACE_4X6_BUTTON_BOX: 8 Vector__XXX
 SG_ reserved : 63|8@0+ (1,0) [0|0] "" Vector__XXX
 SG_ crc16 : 47|16@0+ (1,0) [0|0] "" Vector__XXX
 SG_ submodule_count : 39|8@0+ (1,0) [0|0] "" Vector__XXX
 SG_ node_id : 7|32@0+ (1,0) [0|0] "" Vector__XXX

BO_ 1948 IFACE_ARGB_MULTI: 8 Vector__XXX
 SG_ reserved : 63|8@0+ (1,0) [0|0] "" Vector__XXX
 SG_ crc16 : 47|16@0+ (1,0) [0|0] "" Vector__XXX
 SG_ submodule_count : 39|8@0+ (1,0) [0|0] "" Vector__XXX
 SG_ node_id : 7|32@0+ (1,0) [0|0] "" Vector__XXX

BO_ 1949 IFACE_RESERVED_79D: 8 Vector__XXX
 SG_ reserved : 63|8@0+ (1,0) [0|0] "" Vector__XXX
 SG_ crc16 : 47|16@0+ (1,0) [0|0] "" Vector__XXX
 SG_ submodule_count : 39|8@0+ (1,0) [0|0] "" Vector__XXX
 SG_ node_id : 7|32@0+ (1,0) [0|0] "" Vector__XXX

BO_ 1950 IFACE_RESERVED_79E: 8 Vector__XXX
 SG_ reserved : 63|8@0+ (1,0) [0|0] "" Vector__XXX
 SG_ crc16 : 47|16@0+ (1,0) [0|0] "" Vector__XXX
 SG_ submodule_count : 39|8@0+ (1,0) [0|0] "" Vector__XXX
 SG_ node_id : 7|32@0+ (1,0) [0|0] "" Vector__XXX

BO_ 1951 IFACE_RESERVED_79F: 8 Vector__XXX
 SG_ reserved : 63|8@0+ (1,0) [0|0] "" Vector__XXX
 SG_ crc16 : 47|16@0+ (1,0) [0|0] "" Vector__XXX
 SG_ submodule_count : 39|8@0+ (1,0) [0|0] "" Vector__XXX
 SG_ node_id : 7|32@0+ (1,0) [0|0] "" Vector__XXX

CM_ BO_ 256 "error condition over current";
CM_ BO_ 257 "error condition over temp";
CM_ BO_ 258 "error condition over volt";
CM_ BO_ 259 "general alarm";
CM_ BO_ 260 "node has a stored error to transmit";
CM_ BO_ 261 "canerr reserved 105";
CM_ BO_ 262 "canerr reserved 106";
CM_ BO_ 263 "canerr reserved 107";
CM_ BO_ 264 "canerr reserved 108";
CM_ BO_ 265 "canerr reserved 109";
CM_ BO_ 272 "sw reserved 110";
CM_ BO_ 273 "sw reserved 111";
CM_ BO_ 274 "set switch mode";
CM_ BO_ 275 "switch off";
CM_ BO_ 276 "switch on";
CM_ BO_ 277 "switch momentary press";
CM_ BO_ 278 "set momentary switch duration ms";
CM_ BO_ 279 "switch set pwm duty";
CM_ BO_ 280 "switch set pwm freq";
CM_ BO_ 281 "switch set blink delay in tenths of a second 1-100";
CM_ BO_ 282 "switch set strobe pattern";
CM_ BO_ 283 "enable / disable switch last state memory";
CM_ BO_ 284 "sw reserved 11c";
CM_ BO_ 285 "sw reserved 11d";
CM_ BO_ 286 "sw reserved 11e";
CM_ BO_ 287 "sw reserved 11f";
CM_ BO_ 314 "sw reserved 13a";
CM_ BO_ 315 "sw reserved 13b";
CM_ BO_ 316 "sw reserved 13c";
CM_ BO_ 317 "sw reserved 13d";
CM_ BO_ 318 "sw reserved 13e";
CM_ BO_ 319 "sw reserved 13f";
CM_ BO_ 512 "set display off";
CM_ BO_ 513 "set display on";
CM_ BO_ 514 "set display clear";
CM_ BO_ 515 "set display flash";
CM_ BO_ 516 "set display backlight color";
CM_ BO_ 517 "set display backlight brightness";
CM_ BO_ 518 "req display config";
CM_ BO_ 519 "req display data";
CM_ BO_ 520 "set oled field color";
CM_ BO_ 521 "set oled field blink";
CM_ BO_ 522 "set oled field strobe";
CM_ BO_ 523 "set display reserved 20b";
CM_ BO_ 524 "set display reserved 20c";
CM_ BO_ 525 "display data msg";
CM_ BO_ 526 "display data ack";
CM_ BO_ 527 "set display reserved 20f";
CM_ BO_ 528 "set argb strip color";
CM_ BO_ 529 "set argbw strip color";
CM_ BO_ 530 "set analog strip color";
CM_ BO_ 531 "set addr strip effect";
CM_ BO_ 532 "set led strip brightness";
CM_ BO_ 533 "set led strip off";
CM_ BO_ 534 "set led strip on";
CM_ BO_ 535 "set led reserved 217";
CM_ BO_ 536 "set led reserved 218";
CM_ BO_ 537 "set led reserved 219";
CM_ BO_ 538 "set led reserved 21a";
CM_ BO_ 539 "set led reserved 21b";
CM_ BO_ 540 "set led reserved 21c";
CM_ BO_ 541 "set led reserved 21d";
CM_ BO_ 542 "set led reserved 21e";
CM_ BO_ 543 "set led reserved 21f";
CM_ BO_ 544 "set argb button color";
CM_ BO_ 545 "set argb button led mode";
CM_ BO_ 546 "set button mode 0 disabled, 1 toggle, 2 momentary";
CM_ BO_ 547 "set button reserved 223";
CM_ BO_ 548 "set button reserved 224";
CM_ BO_ 549 "set button reserved 225";
CM_ BO_ 550 "set button reserved 226";
CM_ BO_ 551 "set button reserved 227";
CM_ BO_ 552 "set button reserved 228";
CM_ BO_ 553 "set button reserved 229";
CM_ BO_ 554 "set button reserved 22a";
CM_ BO_ 555 "set button reserved 22b";
CM_ BO_ 556 "set button reserved 22c";
CM_ BO_ 557 "set button reserved 22d";
CM_ BO_ 558 "set button reserved 22e";
CM_ BO_ 559 "set button reserved 22f";
CM_ BO_ 1024 "acknowledge introduction, clear flag on remote device";
CM_ BO_ 1025 "general intro request for all node types";
CM_ BO_ 1026 "message to all nodes to being normal operation, sent after introduction and enumeration are complete";
CM_ BO_ 1027 "message to all nodes to stop transmitting messages and wait for instructions";
CM_ BO_ 1028 "remote nodes should respond with their node id and last boot timestamp";
CM_ BO_ 1029 "remote nodes should respond with diagnostic sensor data";
CM_ BO_ 1030 "req interfaces node include buttons, displays leds and sensors";
CM_ BO_ 1031 "req switch boxes nodes include anything that controls a load";
CM_ BO_ 1032 "req reserved 408";
CM_ BO_ 1033 "req reserved 409";
CM_ BO_ 1034 "req reserved 40a";
CM_ BO_ 1035 "req reserved 40b";
CM_ BO_ 1036 "epoch timestamp from controller";
CM_ BO_ 1037 "controller assigned message id to use for transferring sensor data range 52A:53F";
CM_ BO_ 1038 "req reserved 40e";
CM_ BO_ 1039 "req reserved 40f";
CM_ BO_ 1040 "req digital inputs (gpio type)";
CM_ BO_ 1041 "req digital outputs (gpio type)";
CM_ BO_ 1042 "req displays (eg lcd, oled, argb, led)";
CM_ BO_ 1043 "req temp sensor";
CM_ BO_ 1044 "req volt sensor";
CM_ BO_ 1045 "req amp sensor";
CM_ BO_ 1046 "req analog inputs";
CM_ BO_ 1047 "req ambient light sensors";
CM_ BO_ 1048 "req imu sensors";
CM_ BO_ 1049 "req reserved 419";
CM_ BO_ 1050 "req reserved 41a";
CM_ BO_ 1051 "req reserved 41b";
CM_ BO_ 1052 "req reserved 41c";
CM_ BO_ 1053 "req reserved 41d";
CM_ BO_ 1054 "req reserved 41e";
CM_ BO_ 1055 "req reserved 41f";
CM_ BO_ 1056 "cfg reserved 420";
CM_ BO_ 1057 "cfg reserved 421";
CM_ BO_ 1058 "cfg reserved 422";
CM_ BO_ 1059 "cfg reserved 423";
CM_ BO_ 1060 "cfg reserved 424";
CM_ BO_ 1061 "cfg reserved 425";
CM_ BO_ 1062 "cfg reserved 426";
CM_ BO_ 1063 "cfg reserved 427";
CM_ BO_ 1064 "cfg reserved 428";
CM_ BO_ 1065 "cfg sub raw data";
CM_ BO_ 1066 "node data msg";
CM_ BO_ 1067 "node intro msg";
CM_ BO_ 1068 "sub data msg";
CM_ BO_ 1069 "sub intro msg";
CM_ BO_ 1070 "colorpicker read nvs";
CM_ BO_ 1071 "colorpicker write nvs";
CM_ BO_ 1072 "colorpicker send list";
CM_ BO_ 1073 "colorpicker purge list";
CM_ BO_ 1074 "colorpicker del node";
CM_ BO_ 1075 "colorpicker add node";
CM_ BO_ 1076 "erase nvs";
CM_ BO_ 1077 "reboot";
CM_ BO_ 1078 "write nvs";
CM_ BO_ 1079 "read nvs";
CM_ BO_ 1080 "cfg blink output";
CM_ BO_ 1081 "cfg analog strip";
CM_ BO_ 1082 "cfg argb strip";
CM_ BO_ 1083 "cfg digital input";
CM_ BO_ 1084 "cfg digital output";
CM_ BO_ 1085 "cfg analog input";
CM_ BO_ 1086 "cfg analog output";
CM_ BO_ 1087 "cfg pwm output";
CM_ BO_ 1280 "button down";
CM_ BO_ 1281 "button up";
CM_ BO_ 1282 "keyswitch lock";
CM_ BO_ 1283 "keyswitch unlock";
CM_ BO_ 1284 "dial clockwise";
CM_ BO_ 1285 "dial counter clockwise";
CM_ BO_ 1286 "dial click";
CM_ BO_ 1287 "external current";
CM_ BO_ 1288 "contact closed";
CM_ BO_ 1289 "contact opened";
CM_ BO_ 1290 "internal pcb temp";
CM_ BO_ 1291 "internal pcb volts";
CM_ BO_ 1292 "internal pcb current";
CM_ BO_ 1293 "external temperature";
CM_ BO_ 1294 "external volts";
CM_ BO_ 1295 "adc raw";
CM_ BO_ 1296 "ambient light USE PRIV MSG";
CM_ BO_ 1297 "IMU X Axis USE PRIV MSG";
CM_ BO_ 1298 "IMU Y Axis USE PRIV MSG";
CM_ BO_ 1299 "IMU Z Axis USE PRIV MSG";
CM_ BO_ 1300 "IMU X Gyro USE PRIV MSG";
CM_ BO_ 1301 "IMU Y Gyro USE PRIV MSG";
CM_ BO_ 1302 "IMU Z Gyro USE PRIV MSG";
CM_ BO_ 1303 "IMU temperature";
CM_ BO_ 1304 "analog knob mv";
CM_ BO_ 1305 "data reserved 519";
CM_ BO_ 1306 "node cpu temp";
CM_ BO_ 1307 "node boot timestamp";
CM_ BO_ 1308 "data touchscreen event";
CM_ BO_ 1309 "colorpicker list member";
CM_ BO_ 1310 "colorpicker end of list";
CM_ BO_ 1311 "data reserved 51f";
CM_ BO_ 1312 "display off";
CM_ BO_ 1313 "display on";
CM_ BO_ 1314 "display clear";
CM_ BO_ 1315 "display mode";
CM_ BO_ 1316 "argb button color";
CM_ BO_ 1317 "argb button led mode";
CM_ BO_ 1318 "data config crc";
CM_ BO_ 1319 "data config timestamp";
CM_ BO_ 1320 "data cfgwrite failed";
CM_ BO_ 1321 "data reserved 529";
CM_ BO_ 1322 "0x52A reserved private msg for 64-bit sensor data";
CM_ BO_ 1323 "0x52B reserved private msg for 64-bit sensor data";
CM_ BO_ 1324 "0x52C reserved private msg for 64-bit sensor data";
CM_ BO_ 1325 "0x52D reserved private msg for 64-bit sensor data";
CM_ BO_ 1326 "0x52E reserved private msg for 64-bit sensor data";
CM_ BO_ 1327 "0x52F reserved private msg for 64-bit sensor data";
CM_ BO_ 1328 "0x530 reserved private msg for 64-bit sensor data";
CM_ BO_ 1329 "0x531 reserved private msg for 64-bit sensor data";
CM_ BO_ 1330 "0x532 reserved private msg for 64-bit sensor data";
CM_ BO_ 1331 "0x533 reserved private msg for 64-bit sensor data";
CM_ BO_ 1332 "0x534 reserved private msg for 64-bit sensor data";
CM_ BO_ 1333 "0x535 reserved private msg for 64-bit sensor data";
CM_ BO_ 1334 "0x536 reserved private msg for 64-bit sensor data";
CM_ BO_ 1335 "0x537 reserved private msg for 64-bit sensor data";
CM_ BO_ 1336 "0x538 reserved private msg for 64-bit sensor data";
CM_ BO_ 1337 "0x539 reserved private msg for 64-bit sensor data";
CM_ BO_ 1338 "0x53A reserved private msg for 64-bit sensor data";
CM_ BO_ 1339 "0x53B reserved private msg for 64-bit sensor data";
CM_ BO_ 1340 "0x53C reserved private msg for 64-bit sensor data";
CM_ BO_ 1341 "0x53D reserved private msg for 64-bit sensor data";
CM_ BO_ 1342 "0x53E reserved private msg for 64-bit sensor data";
CM_ BO_ 1343 "0x53F reserved private msg for 64-bit sensor data";
CM_ BO_ 1792 "analog led strip";
CM_ BO_ 1793 "argb button backlight";
CM_ BO_ 1794 "argb led strip";
CM_ BO_ 1795 "strobe module";
CM_ BO_ 1796 "disp reserved 704";
CM_ BO_ 1797 "non-touch oled display";
CM_ BO_ 1798 "disp reserved 706";
CM_ BO_ 1799 "non touch lcd";
CM_ BO_ 1800 "disp no backlight";
CM_ BO_ 1801 "disp argb backlight";
CM_ BO_ 1802 "disp analog backlight";
CM_ BO_ 1803 "disp touchscreen lcd";
CM_ BO_ 1804 "monochrome led";
CM_ BO_ 1805 "disp reserved 70d";
CM_ BO_ 1806 "disp reserved 70e";
CM_ BO_ 1807 "disp reserved 70f";
CM_ BO_ 1808 "input analog adc";
CM_ BO_ 1809 "input digital gpio";
CM_ BO_ 1810 "input reserved 712";
CM_ BO_ 1811 "input virtual keypad";
CM_ BO_ 1812 "analog knob input";
CM_ BO_ 1813 "jog dial with click";
CM_ BO_ 1814 "jog dial without click";
CM_ BO_ 1815 "motion detector";
CM_ BO_ 1816 "capacitive touch switch stand-alone";
CM_ BO_ 1817 "input reserved 719";
CM_ BO_ 1818 "input reserved 71a";
CM_ BO_ 1819 "input reserved 71b";
CM_ BO_ 1820 "input reserved 71c";
CM_ BO_ 1821 "input reserved 71d";
CM_ BO_ 1822 "input reserved 71e";
CM_ BO_ 1823 "input reserved 71f";
CM_ BO_ 1824 "sensor digital temp";
CM_ BO_ 1825 "sensor ktype temp";
CM_ BO_ 1826 "sensor node last boot timestamp";
CM_ BO_ 1827 "sensor node pcb temp";
CM_ BO_ 1828 "sensor node cpu temp";
CM_ BO_ 1829 "sensor ext voltage";
CM_ BO_ 1830 "sensor int voltage";
CM_ BO_ 1831 "sensor int current";
CM_ BO_ 1832 "sensor ext current shunt";
CM_ BO_ 1833 "sensor ext current hall";
CM_ BO_ 1834 "sensor reserved 72a";
CM_ BO_ 1835 "sensor reserved 72b";
CM_ BO_ 1836 "sensor reserved 72c";
CM_ BO_ 1837 "sensor reserved 72d";
CM_ BO_ 1838 "sensor reserved 72e";
CM_ BO_ 1839 "sensor reserved 72f";
CM_ BO_ 1840 "input ambient light";
CM_ BO_ 1841 "IMU X Axis sensor";
CM_ BO_ 1842 "IMU Y Axis sensor";
CM_ BO_ 1843 "IMU Z Axis sensor";
CM_ BO_ 1844 "IMU X Gyro sensor";
CM_ BO_ 1845 "IMU Y Gyro sensor";
CM_ BO_ 1846 "IMU Z Gyro sensor";
CM_ BO_ 1847 "IMU temp sensor";
CM_ BO_ 1848 "GPS utc time";
CM_ BO_ 1849 "GPS latitude";
CM_ BO_ 1850 "GPS NS IND";
CM_ BO_ 1851 "GPS longitude";
CM_ BO_ 1852 "GPS EW IND";
CM_ BO_ 1853 "GPS altitude";
CM_ BO_ 1854 "GPS status";
CM_ BO_ 1855 "sensor2 reserved 73f";
CM_ BO_ 1856 "high current solid state switch";
CM_ BO_ 1857 "low current solid state switch";
CM_ BO_ 1858 "open drain output";
CM_ BO_ 1859 "mechanical relay";
CM_ BO_ 1860 "gpio digital";
CM_ BO_ 1861 "gpio pwm";
CM_ BO_ 1862 "gpio dac";
CM_ BO_ 1863 "out reserved 747";
CM_ BO_ 1864 "out reserved 748";
CM_ BO_ 1865 "out reserved 749";
CM_ BO_ 1866 "out reserved 74a";
CM_ BO_ 1867 "out reserved 74b";
CM_ BO_ 1868 "out reserved 74c";
CM_ BO_ 1869 "out reserved 74d";
CM_ BO_ 1870 "out reserved 74e";
CM_ BO_ 1871 "out reserved 74f";
CM_ BO_ 1872 "intro reserved 750";
CM_ BO_ 1873 "intro reserved 751";
CM_ BO_ 1874 "intro reserved 752";
CM_ BO_ 1875 "intro reserved 753";
CM_ BO_ 1876 "intro reserved 754";
CM_ BO_ 1877 "intro reserved 755";
CM_ BO_ 1878 "intro reserved 756";
CM_ BO_ 1879 "intro reserved 757";
CM_ BO_ 1880 "intro reserved 758";
CM_ BO_ 1881 "intro reserved 759";
CM_ BO_ 1882 "intro reserved 75a";
CM_ BO_ 1883 "intro reserved 75b";
CM_ BO_ 1884 "intro reserved 75c";
CM_ BO_ 1885 "intro reserved 75d";
CM_ BO_ 1886 "intro reserved 75e";
CM_ BO_ 1887 "intro reserved 75f";
CM_ BO_ 1888 "sys reserved 760";
CM_ BO_ 1889 "sys reserved 761";
CM_ BO_ 1890 "sys reserved 762";
CM_ BO_ 1891 "sys reserved 763";
CM_ BO_ 1892 "sys reserved 764";
CM_ BO_ 1893 "sys reserved 765";
CM_ BO_ 1894 "sys reserved 766";
CM_ BO_ 1895 "sys reserved 767";
CM_ BO_ 1896 "sys reserved 768";
CM_ BO_ 1897 "sys reserved 769";
CM_ BO_ 1898 "sys reserved 76a";
CM_ BO_ 1899 "sys reserved 76b";
CM_ BO_ 1900 "sys reserved 76c";
CM_ BO_ 1901 "sys reserved 76d";
CM_ BO_ 1902 "sys reserved 76e";
CM_ BO_ 1903 "sys reserved 76f";
CM_ BO_ 1904 "sys reserved 770";
CM_ BO_ 1905 "sys reserved 771";
CM_ BO_ 1906 "sys reserved 772";
CM_ BO_ 1907 "sys reserved 773";
CM_ BO_ 1908 "sys reserved 774";
CM_ BO_ 1909 "sys reserved 775";
CM_ BO_ 1910 "sys reserved 776";
CM_ BO_ 1911 "sys reserved 777";
CM_ BO_ 1912 "sys reserved 778";
CM_ BO_ 1913 "sys reserved 779";
CM_ BO_ 1914 "sys reserved 77a";
CM_ BO_ 1915 "sys reserved 77b";
CM_ BO_ 1916 "sys reserved 77c";
CM_ BO_ 1917 "sys reserved 77d";
CM_ BO_ 1918 "sys reserved 77e";
CM_ BO_ 1919 "sys reserved 77f";
CM_ BO_ 1920 "3 gang switch box, 2 high, 1 low";
CM_ BO_ 1921 "4-gang switch box, 2 high, 2 low";
CM_ BO_ 1922 "6-gang switch box, 4 high, 2 low";
CM_ BO_ 1923 "6-gang switch box, 2 high, 4 low";
CM_ BO_ 1924 "2-gang switch box, 2 high";
CM_ BO_ 1925 "2-gang switch box, 2 low";
CM_ BO_ 1926 "4-digital multi temp input box";
CM_ BO_ 1927 "4-gang relay output box";
CM_ BO_ 1928 "temp, volt, current input box";
CM_ BO_ 1929 "8-gang relay output box";
CM_ BO_ 1930 "input - output box, 4 in, 4 out";
CM_ BO_ 1931 "input - output box, multiple options";
CM_ BO_ 1932 "box reserved 78c";
CM_ BO_ 1933 "box reserved 78d";
CM_ BO_ 1934 "box reserved 78e";
CM_ BO_ 1935 "box reserved 78f";
CM_ BO_ 1936 "8x4 argb keypad";
CM_ BO_ 1937 "4x4 argb keypad";
CM_ BO_ 1938 "touchscreen type a";
CM_ BO_ 1939 "touchscreen type b";
CM_ BO_ 1940 "nextion type a";
CM_ BO_ 1941 "nextion type b";
CM_ BO_ 1942 "iface reserved 796";
CM_ BO_ 1943 "iface reserved 797";
CM_ BO_ 1944 "iface reserved 798";
CM_ BO_ 1945 "6 axis imu";
CM_ BO_ 1946 "3x5 button box";
CM_ BO_ 1947 "4x6 button box";
CM_ BO_ 1948 "iface ARGB multi";
CM_ BO_ 1949 "iface reserved 79d";
CM_ BO_ 1950 "iface reserved 79e";
CM_ BO_ 1951 "iface reserved 79f";
